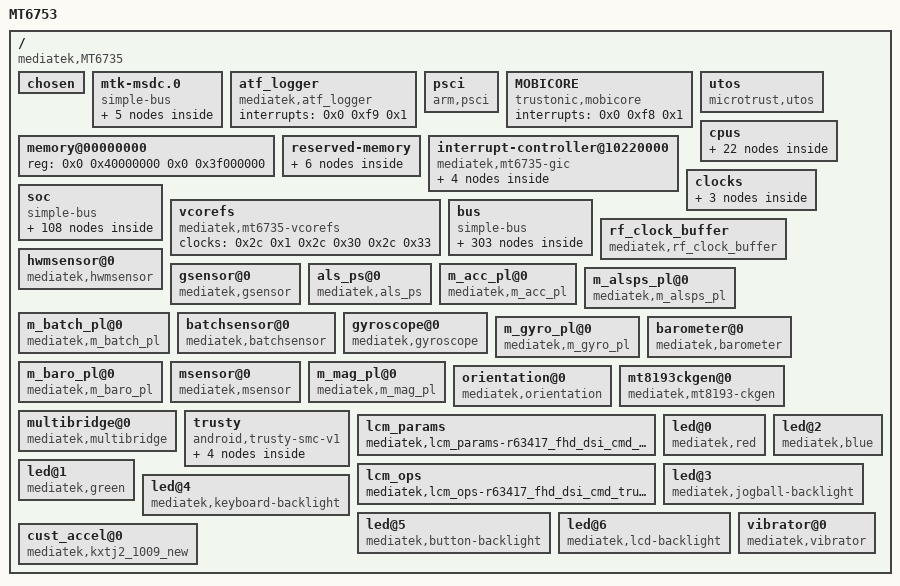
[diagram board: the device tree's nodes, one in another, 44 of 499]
/dts-v1/;

/ {
	model = "MT6753";
	compatible = "mediatek,MT6735";
	interrupt-parent = <0x1>;
	#address-cells = <0x2>;
	#size-cells = <0x2>;

	chosen {
		bootargs = "console=tty0 console=ttyMT0,921600n1 root=/dev/ram initrd=0x44000000,0x300000 loglevel=8 androidboot.hardware=mt6735";
	};

	mtk-msdc.0 {
		compatible = "simple-bus";
		#address-cells = <0x1>;
		#size-cells = <0x1>;
		ranges = <0x0 0x0 0x0 0xffffffff>;

		msdc0@11230000 {
			compatible = "mediatek,mt6753-mmc";
			reg = <0x11230000 0x10000 0x10000e84 0x2>;
			interrupts = <0x0 0x4f 0x8>;
			status = "okay";
			clk_src = [02];
			bus-width = <0x8>;
			max-frequency = <0xbebc200>;
			cap-mmc-highspeed;
			msdc-sys-suspend;
			mmc-ddr-1_8v;
			mmc-hs200-1_8v;
			mmc-hs400-1_8v;
			non-removable;
			pinctl = <0x2>;
			register_setting = <0x3>;
			host_function = [00];
			bootable;
		};

		msdc1@11240000 {
			compatible = "mediatek,mt6753-mmc";
			reg = <0x11240000 0x10000 0x10000e84 0x2>;
			interrupts = <0x0 0x50 0x8>;
			status = "okay";
			clk_src = [02];
			bus-width = <0x4>;
			max-frequency = <0xbebc200>;
			msdc-sys-suspend;
			sd_need_power;
			cap-sd-highspeed;
			sd-uhs-sdr12;
			sd-uhs-sdr25;
			sd-uhs-sdr50;
			sd-uhs-ddr50;
			pinctl = <0x4>;
			pinctl_sdr104 = <0x5>;
			pinctl_sdr50 = <0x6>;
			pinctl_ddr50 = <0x7>;
			register_setting = <0x8>;
			host_function = [01];
			cd_level = [00];
			cd-gpios = <0x9 0x4c 0x0>;
		};

		msdc2@11250000 {
			compatible = "mediatek,mt6735-mmc";
			reg = <0x11250000 0x10000 0x10000e84 0x2>;
			interrupts = <0x0 0x51 0x8>;
			status = "okay";
			clocks = <0xa 0x10>;
			clock-names = "MSDC2-CLOCK";
			clk_src = [02];
			bus-width = <0x4>;
			max-frequency = <0xbebc200>;
			cap-sd-highspeed;
			sd-uhs-sdr12;
			sd-uhs-sdr25;
			sd-uhs-sdr50;
			sd-uhs-sdr104;
			sd-uhs-ddr50;
			non-removable;
			host_function = [02];
		};

		msdc3@11260000 {
			compatible = "mediatek,mt6735-mmc";
			reg = <0x11260000 0x10000 0x10000e84 0x2>;
			interrupts = <0x0 0x52 0x8>;
			status = "disabled";
			clocks = <0xa 0x11>;
			clock-names = "MSDC3-CLOCK";
		};

		default {
			compatible = "mediatek, msdc1_ins-eint";
			interrupt-parent = <0xb>;
			interrupts = <0x4c 0x8>;
			debounce = <0x4c 0x3e8>;
			status = "okay";
		};
	};

	atf_logger {
		compatible = "mediatek,atf_logger";
		interrupts = <0x0 0xf9 0x1>;
	};

	psci {
		compatible = "arm,psci";
		method = "smc";
		cpu_suspend = <0x84000001>;
		cpu_off = <0x84000002>;
		cpu_on = <0x84000003>;
		affinity_info = <0x84000004>;
	};

	MOBICORE {
		compatible = "trustonic,mobicore";
		interrupts = <0x0 0xf8 0x1>;
	};

	utos {
		compatible = "microtrust,utos";
		interrupts = <0x0 0xf4 0x1 0x0 0xf5 0x1 0x0 0xf6 0x1 0x0 0xfa 0x1 0x0 0xfb 0x1 0x0 0xfc 0x1 0x0 0xfd 0x1 0x0 0xff 0x1>;
	};

	cpus {
		#address-cells = <0x1>;
		#size-cells = <0x0>;

		cpu@000 {
			device_type = "cpu";
			compatible = "arm,cortex-a53";
			reg = <0x0>;
			enable-method = "mt-boot";
			cpu-idle-states = <0xc 0xc 0xd 0xd>;
			cpu-release-addr = <0x0 0x40000200>;
			clock-frequency = "M|m";
			linux,phandle = <0xe>;
			phandle = <0xe>;
		};

		cpu@001 {
			device_type = "cpu";
			compatible = "arm,cortex-a53";
			reg = <0x1>;
			enable-method = "mt-boot";
			cpu-idle-states = <0xc 0xc 0xd 0xd>;
			cpu-release-addr = <0x0 0x40000200>;
			clock-frequency = "M|m";
			linux,phandle = <0xf>;
			phandle = <0xf>;
		};

		cpu@002 {
			device_type = "cpu";
			compatible = "arm,cortex-a53";
			reg = <0x2>;
			enable-method = "mt-boot";
			cpu-idle-states = <0xc 0xc 0xd 0xd>;
			cpu-release-addr = <0x0 0x40000200>;
			clock-frequency = "M|m";
			linux,phandle = <0x10>;
			phandle = <0x10>;
		};

		cpu@003 {
			device_type = "cpu";
			compatible = "arm,cortex-a53";
			reg = <0x3>;
			enable-method = "mt-boot";
			cpu-idle-states = <0xc 0xc 0xd 0xd>;
			cpu-release-addr = <0x0 0x40000200>;
			clock-frequency = "M|m";
			linux,phandle = <0x11>;
			phandle = <0x11>;
		};

		cpu@100 {
			device_type = "cpu";
			compatible = "arm,cortex-a53";
			reg = <0x100>;
			enable-method = "mt-boot";
			cpu-idle-states = <0xc 0xc 0xd 0xd>;
			cpu-release-addr = <0x0 0x40000200>;
			clock-frequency = "M|m";
			linux,phandle = <0x12>;
			phandle = <0x12>;
		};

		cpu@101 {
			device_type = "cpu";
			compatible = "arm,cortex-a53";
			reg = <0x101>;
			enable-method = "mt-boot";
			cpu-idle-states = <0xc 0xc 0xd 0xd>;
			cpu-release-addr = <0x0 0x40000200>;
			clock-frequency = "M|m";
			linux,phandle = <0x13>;
			phandle = <0x13>;
		};

		cpu@102 {
			device_type = "cpu";
			compatible = "arm,cortex-a53";
			reg = <0x102>;
			enable-method = "mt-boot";
			cpu-idle-states = <0xc 0xc 0xd 0xd>;
			cpu-release-addr = <0x0 0x40000200>;
			clock-frequency = "M|m";
			linux,phandle = <0x14>;
			phandle = <0x14>;
		};

		cpu@103 {
			device_type = "cpu";
			compatible = "arm,cortex-a53";
			reg = <0x103>;
			enable-method = "mt-boot";
			cpu-idle-states = <0xc 0xc 0xd 0xd>;
			cpu-release-addr = <0x0 0x40000200>;
			clock-frequency = "M|m";
			linux,phandle = <0x15>;
			phandle = <0x15>;
		};

		cpu-map {

			cluster0 {

				core0 {
					cpu = <0xe>;
				};

				core1 {
					cpu = <0xf>;
				};

				core2 {
					cpu = <0x10>;
				};

				core3 {
					cpu = <0x11>;
				};
			};

			cluster1 {

				core0 {
					cpu = <0x12>;
				};

				core1 {
					cpu = <0x13>;
				};

				core2 {
					cpu = <0x14>;
				};

				core3 {
					cpu = <0x15>;
				};
			};
		};

		idle-states {
			entry-method = "arm,psci";

			cpu-sleep-0-0 {
				compatible = "arm,idle-state";
				arm,psci-suspend-param = <0x10000>;
				entry-latency-us = <0x258>;
				exit-latency-us = <0x258>;
				min-residency-us = <0x4b0>;
				linux,phandle = <0xd>;
				phandle = <0xd>;
			};

			cluster-sleep-0 {
				compatible = "arm,idle-state";
				arm,psci-suspend-param = <0x1010000>;
				entry-latency-us = <0x320>;
				exit-latency-us = <0x3e8>;
				min-residency-us = <0x7d0>;
				linux,phandle = <0xc>;
				phandle = <0xc>;
			};
		};
	};

	memory@00000000 {
		device_type = "memory";
		reg = <0x0 0x40000000 0x0 0x3f000000>;
	};

	reserved-memory {
		#address-cells = <0x2>;
		#size-cells = <0x2>;
		ranges;

		atf-reserved-memory@43000000 {
			compatible = "mediatek,mt6735-atf-reserved-memory", "mediatek,mt6735m-atf-reserved-memory", "mediatek,mt6753-atf-reserved-memory";
			no-map;
			reg = <0x0 0x43000000 0x0 0x30000>;
		};

		reserve-memory-ccci_md1 {
			compatible = "mediatek,reserve-memory-ccci_md1";
			no-map;
			size = <0x0 0x3810000>;
			alignment = <0x0 0x2000000>;
			alloc-ranges = <0x0 0x40000000 0x0 0xc0000000>;
		};

		consys-reserve-memory {
			compatible = "mediatek,consys-reserve-memory";
			no-map;
			size = <0x0 0x100000>;
			alignment = <0x0 0x200000>;
		};

		ram_console-reserved-memory@43f00000 {
			compatible = "mediatek,ram_console";
			reg = <0x0 0x43f00000 0x0 0x10000>;
		};

		minirdump-reserved-memory@43ff0000 {
			compatible = "mediatek, minirdump";
			reg = <0x0 0x43ff0000 0x0 0x10000>;
		};

		pstore-reserved-memory@43f10000 {
			compatible = "mediatek,pstore";
			reg = <0x0 0x43f10000 0x0 0xe0000>;
		};
	};

	interrupt-controller@10220000 {
		compatible = "mediatek,mt6735-gic";
		#interrupt-cells = <0x3>;
		#address-cells = <0x0>;
		interrupt-controller;
		reg = <0x0 0x10221000 0x0 0x1000 0x0 0x10222000 0x0 0x1000 0x0 0x10200620 0x0 0x1000>;
		mediatek,wdt_irq = <0xa0>;
		linux,phandle = <0x1>;
		phandle = <0x1>;

		gic-cpuif@0 {
			compatible = "arm,gic-cpuif";
			cpuif-id = <0x0>;
			cpu = <0xe>;
		};

		gic-cpuif@1 {
			compatible = "arm,gic-cpuif";
			cpuif-id = <0x1>;
			cpu = <0xf>;
		};

		gic-cpuif@2 {
			compatible = "arm,gic-cpuif";
			cpuif-id = <0x2>;
			cpu = <0x10>;
		};

		gic-cpuif@3 {
			compatible = "arm,gic-cpuif";
			cpuif-id = <0x3>;
			cpu = <0x11>;
		};
	};

	clocks {

		clk_null {
			compatible = "fixed-clock";
			#clock-cells = <0x0>;
			clock-frequency = <0x0>;
		};

		clk26m {
			compatible = "fixed-clock";
			#clock-cells = <0x0>;
			clock-frequency = <0x18cba80>;
		};

		clk32k {
			compatible = "fixed-clock";
			#clock-cells = <0x0>;
			clock-frequency = <0x7d00>;
		};
	};

	soc {
		compatible = "simple-bus";
		#address-cells = <0x1>;
		#size-cells = <0x1>;
		ranges;

		chipid@08000000 {
			compatible = "mediatek,chipid";
			reg = <0x8000000 0x4 0x8000004 0x4 0x8000008 0x4 0x800000c 0x4>;
		};

		topckgen@0x10210000 {
			compatible = "mediatek,mt6735-topckgen";
			reg = <0x10210000 0x1000>;
			#clock-cells = <0x1>;
			linux,phandle = <0x2c>;
			phandle = <0x2c>;
		};

		infrasys@0x10000000 {
			compatible = "mediatek,mt6735-infrasys";
			reg = <0x10000000 0x1000>;
			#clock-cells = <0x1>;
			linux,phandle = <0x16>;
			phandle = <0x16>;
		};

		perisys@0x10002000 {
			compatible = "mediatek,mt6735-perisys";
			reg = <0x10002000 0x1000>;
			#clock-cells = <0x1>;
			linux,phandle = <0xa>;
			phandle = <0xa>;
		};

		gpio {
			compatible = "mediatek,gpio_usage_mapping";
			GPIO_SIM1_HOT_PLUG = <0x8>;
			GPIO_SIM2_SCLK = <0xa0>;
			GPIO_SIM2_SRST = <0xa1>;
			GPIO_SIM2_SIO = <0xa2>;
			GPIO_SIM1_SCLK = <0xa3>;
			GPIO_SIM1_SRST = <0xa4>;
			GPIO_SIM1_SIO = <0xa5>;
		};

		gpio@10211000 {
			compatible = "mediatek,gpio";
			reg = <0x10211000 0x1000>;
		};

		dramc_nao@1020e000 {
			compatible = "mediatek,mt6735-dramc_nao";
			reg = <0x1020e000 0x1000>;
		};

		ddrphy@10213000 {
			compatible = "mediatek,mt6735-ddrphy";
			reg = <0x10213000 0x1000>;
		};

		dramc@10214000 {
			compatible = "mediatek,mt6735-dramc";
			reg = <0x10214000 0x1000>;
			clocks = <0x16 0x2>;
			clock-names = "infra-cqdma";
		};

		cpuxgpt@10200000 {
			compatible = "mediatek,mt6735-cpuxgpt";
			reg = <0x10200000 0x1000>;
			interrupts = <0x0 0x40 0x4 0x0 0x41 0x4 0x0 0x42 0x4 0x0 0x43 0x4 0x0 0x44 0x4 0x0 0x45 0x4 0x0 0x46 0x4 0x0 0x47 0x4>;
		};

		apxgpt@10004000 {
			compatible = "mediatek,mt6735-apxgpt";
			reg = <0x10004000 0x1000>;
			interrupts = <0x0 0x98 0x8>;
			clock-frequency = <0xc65d40>;
		};

		pmu {
			compatible = "arm,armv8-pmuv3";
			interrupts = <0x0 0x8 0x8 0x0 0x9 0x8 0x0 0xa 0x8 0x0 0xb 0x8 0x0 0xc 0x8 0x0 0xd 0x8 0x0 0xe 0x8 0x0 0xf 0x8>;
			interrupt-affinity = <0xe 0xf 0x10 0x11 0x12 0x13 0x14 0x15>;
		};

		timer {
			compatible = "arm,armv8-timer";
			interrupts = <0x1 0xd 0x8 0x1 0xe 0x8 0x1 0xb 0x8 0x1 0xa 0x8>;
			clock-frequency = <0xc65d40>;
		};

		mt_pmic_regulator {
			compatible = "mediatek,mt_pmic";

			buck_regulators {
				compatible = "mediatek,mt_pmic_buck_regulators";

				buck_vpa {
					regulator-name = "vpa";
					regulator-min-microvolt = <0x7a120>;
					regulator-max-microvolt = <0x37b1d0>;
					regulator-ramp-delay = <0xc350>;
					regulator-enable-ramp-delay = <0xb4>;
				};

				buck_vproc {
					regulator-name = "vproc";
					regulator-min-microvolt = <0x927c0>;
					regulator-max-microvolt = <0x154456>;
					regulator-ramp-delay = <0x186a>;
					regulator-enable-ramp-delay = <0xb4>;
					regulator-always-on;
					regulator-boot-on;
				};

				buck_vcore1 {
					regulator-name = "vcore1";
					regulator-min-microvolt = <0x927c0>;
					regulator-max-microvolt = <0x154456>;
					regulator-ramp-delay = <0x186a>;
					regulator-enable-ramp-delay = <0xb4>;
					regulator-always-on;
					regulator-boot-on;
				};

				buck_vsys22 {
					regulator-name = "vsys22";
					regulator-min-microvolt = <0x124f80>;
					regulator-max-microvolt = <0x1e6c16>;
					regulator-ramp-delay = <0x186a>;
					regulator-enable-ramp-delay = <0xb4>;
					regulator-always-on;
					regulator-boot-on;
				};

				buck_vlte {
					regulator-name = "vlte";
					regulator-min-microvolt = <0x927c0>;
					regulator-max-microvolt = <0x154456>;
					regulator-ramp-delay = <0x186a>;
					regulator-enable-ramp-delay = <0xb4>;
					regulator-always-on;
					regulator-boot-on;
				};
			};

			ldo_regulators {
				compatible = "mediatek,mt_pmic_ldo_regulators";

				ldo_vaux18 {
					regulator-name = "vaux18";
					regulator-min-microvolt = <0x1b7740>;
					regulator-max-microvolt = <0x1b7740>;
					regulator-enable-ramp-delay = <0x108>;
					regulator-boot-on;
					linux,phandle = <0x17>;
					phandle = <0x17>;
				};

				ldo_vtcxo_0 {
					regulator-name = "vtcxo_0";
					regulator-min-microvolt = <0x2ab980>;
					regulator-max-microvolt = <0x2ab980>;
					regulator-enable-ramp-delay = <0x6e>;
					regulator-boot-on;
					linux,phandle = <0x18>;
					phandle = <0x18>;
				};

				ldo_vtcxo_1 {
					regulator-name = "vtcxo_1";
					regulator-min-microvolt = <0x2ab980>;
					regulator-max-microvolt = <0x2ab980>;
					regulator-enable-ramp-delay = <0x6e>;
					linux,phandle = <0x19>;
					phandle = <0x19>;
				};

				ldo_vaud28 {
					regulator-name = "vaud28";
					regulator-min-microvolt = <0x2ab980>;
					regulator-max-microvolt = <0x2ab980>;
					regulator-enable-ramp-delay = <0x108>;
					regulator-boot-on;
					linux,phandle = <0x1a>;
					phandle = <0x1a>;
				};

				ldo_vcn28 {
					regulator-name = "vcn28";
					regulator-min-microvolt = <0x2ab980>;
					regulator-max-microvolt = <0x2ab980>;
					regulator-enable-ramp-delay = <0x108>;
				};

				ldo_vcama {
					regulator-name = "vcama";
					regulator-min-microvolt = <0x16e360>;
					regulator-max-microvolt = <0x2ab980>;
					regulator-enable-ramp-delay = <0x108>;
					regulator-default-on = <0x0>;
					status = "okay";
					linux,phandle = <0x38>;
					phandle = <0x38>;
				};

				ldo_vcn33_bt {
					regulator-name = "vcn33_bt";
					regulator-min-microvolt = <0x325aa0>;
					regulator-max-microvolt = <0x36ee80>;
					regulator-enable-ramp-delay = <0x108>;
				};

				ldo_vcn33_wifi {
					regulator-name = "vcn33_wifi";
					regulator-min-microvolt = <0x325aa0>;
					regulator-max-microvolt = <0x36ee80>;
					regulator-enable-ramp-delay = <0x108>;
				};

				ldo_vusb33 {
					regulator-name = "vusb33";
					regulator-min-microvolt = <0x325aa0>;
					regulator-max-microvolt = <0x325aa0>;
					regulator-enable-ramp-delay = <0x108>;
					regulator-boot-on;
					linux,phandle = <0x62>;
					phandle = <0x62>;
				};

				ldo_vefuse {
					regulator-name = "vefuse";
					regulator-min-microvolt = <0x1b7740>;
					regulator-max-microvolt = <0x2191c0>;
					regulator-enable-ramp-delay = <0x108>;
					linux,phandle = <0x1b>;
					phandle = <0x1b>;
				};

				ldo_vsim1 {
					regulator-name = "vsim1";
					regulator-min-microvolt = <0x19f0a0>;
					regulator-max-microvolt = <0x200b20>;
					regulator-enable-ramp-delay = <0x108>;
					regulator-default-on = <0x0>;
					status = "okay";
					linux,phandle = <0x1c>;
					phandle = <0x1c>;
				};

				ldo_vsim2 {
					regulator-name = "vsim2";
					regulator-min-microvolt = <0x19f0a0>;
					regulator-max-microvolt = <0x200b20>;
					regulator-enable-ramp-delay = <0x108>;
					regulator-default-on = <0x0>;
					status = "okay";
					linux,phandle = <0x1d>;
					phandle = <0x1d>;
				};

				ldo_vemc_3v3 {
					regulator-name = "vemc_3v3";
					regulator-min-microvolt = <0x1b7740>;
					regulator-max-microvolt = <0x325aa0>;
					regulator-enable-ramp-delay = <0x108>;
					regulator-boot-on;
					linux,phandle = <0x1e>;
					phandle = <0x1e>;
				};

				ldo_vmch {
					regulator-name = "vmch";
					regulator-min-microvolt = <0x2c4020>;
					regulator-max-microvolt = <0x325aa0>;
					regulator-enable-ramp-delay = <0x2c>;
					linux,phandle = <0x1f>;
					phandle = <0x1f>;
				};

				ldo_vtref {
					regulator-name = "vtref";
					regulator-min-microvolt = <0x1b7740>;
					regulator-max-microvolt = <0x1b7740>;
					regulator-enable-ramp-delay = <0xf0>;
					linux,phandle = <0x20>;
					phandle = <0x20>;
				};

				ldo_vmc {
					regulator-name = "vmc";
					regulator-min-microvolt = <0x1b7740>;
					regulator-max-microvolt = <0x325aa0>;
					regulator-enable-ramp-delay = <0x2c>;
					linux,phandle = <0x21>;
					phandle = <0x21>;
				};

				ldo_vcamaf {
					regulator-name = "vcamaf";
					regulator-min-microvolt = <0x124f80>;
					regulator-max-microvolt = <0x325aa0>;
					regulator-enable-ramp-delay = <0x108>;
					regulator-default-on = <0x0>;
					status = "okay";
					linux,phandle = <0x3a>;
					phandle = <0x3a>;
				};

				ldo_vio28 {
					regulator-name = "vio28";
					regulator-min-microvolt = <0x2ab980>;
					regulator-max-microvolt = <0x2ab980>;
					regulator-enable-ramp-delay = <0x108>;
					regulator-boot-on;
					linux,phandle = <0x22>;
					phandle = <0x22>;
				};

				ldo_vgp1 {
					regulator-name = "vgp1";
					regulator-min-microvolt = <0x124f80>;
					regulator-max-microvolt = <0x325aa0>;
					regulator-enable-ramp-delay = <0x108>;
					regulator-default-on = <0x0>;
					status = "okay";
					linux,phandle = <0x71>;
					phandle = <0x71>;
				};

				ldo_vibr {
					regulator-name = "vibr";
					regulator-min-microvolt = <0x124f80>;
					regulator-max-microvolt = <0x325aa0>;
					regulator-enable-ramp-delay = <0x2c>;
					regulator-default-on = <0x0>;
					status = "okay";
					linux,phandle = <0x23>;
					phandle = <0x23>;
				};

				ldo_vcamd {
					regulator-name = "vcamd";
					regulator-min-microvolt = <0xdbba0>;
					regulator-max-microvolt = <0x16e360>;
					regulator-enable-ramp-delay = <0x108>;
					regulator-default-on = <0x0>;
					status = "okay";
					linux,phandle = <0x39>;
					phandle = <0x39>;
				};

				ldo_vrf18_0 {
					regulator-name = "vrf18_0";
					regulator-min-microvolt = <0x1bd8e8>;
					regulator-max-microvolt = <0x1bd8e8>;
					regulator-enable-ramp-delay = <0xdc>;
					linux,phandle = <0x24>;
					phandle = <0x24>;
				};

				ldo_vrf18_1 {
					regulator-name = "vrf18_1";
					regulator-min-microvolt = <0x124f80>;
					regulator-max-microvolt = <0x1bd8e8>;
					regulator-enable-ramp-delay = <0xdc>;
					linux,phandle = <0x25>;
					phandle = <0x25>;
				};

				ldo_vio18 {
					regulator-name = "vio18";
					regulator-min-microvolt = <0x1b7740>;
					regulator-max-microvolt = <0x1b7740>;
					regulator-enable-ramp-delay = <0x108>;
					regulator-boot-on;
					linux,phandle = <0x26>;
					phandle = <0x26>;
				};

				ldo_vcn18 {
					regulator-name = "vcn18";
					regulator-min-microvolt = <0x1b7740>;
					regulator-max-microvolt = <0x1b7740>;
					regulator-enable-ramp-delay = <0x2c>;
				};

				ldo_vcamio {
					regulator-name = "vcamio";
					regulator-min-microvolt = <0x124f80>;
					regulator-max-microvolt = <0x1b7740>;
					regulator-enable-ramp-delay = <0xdc>;
					regulator-default-on = <0x0>;
					status = "okay";
					linux,phandle = <0x3b>;
					phandle = <0x3b>;
				};

				ldo_vsram {
					regulator-name = "vsram";
					regulator-min-microvolt = <0xaae60>;
					regulator-max-microvolt = <0x16caf6>;
					regulator-enable-ramp-delay = <0xdc>;
					regulator-ramp-delay = <0x186a>;
					regulator-boot-on;
					linux,phandle = <0x27>;
					phandle = <0x27>;
				};

				ldo_vm {
					regulator-name = "vm";
					regulator-min-microvolt = <0x12ebc0>;
					regulator-max-microvolt = <0x177fa0>;
					regulator-enable-ramp-delay = <0x108>;
					regulator-boot-on;
					linux,phandle = <0x28>;
					phandle = <0x28>;
				};
			};

			regulators_supply {
				compatible = "mediatek,mt_pmic_regulator_supply";
				vaux18-supply = <0x17>;
				vtcxo_0-supply = <0x18>;
				vtcxo_1-supply = <0x19>;
				vaud28-supply = <0x1a>;
				vefuse-supply = <0x1b>;
				vsim1-supply = <0x1c>;
				vsim2-supply = <0x1d>;
				vemc_3v3-supply = <0x1e>;
				vmch-supply = <0x1f>;
				vtref-supply = <0x20>;
				vmc-supply = <0x21>;
				vio28-supply = <0x22>;
				vibr-supply = <0x23>;
				vrf18_0-supply = <0x24>;
				vrf18_1-supply = <0x25>;
				vio18-supply = <0x26>;
				vsram-supply = <0x27>;
				vm-supply = <0x28>;
			};
		};

		sys_cirq@10204000 {
			compatible = "mediatek,mt6735-sys_cirq";
			reg = <0x10204000 0x1000>;
			interrupts = <0x0 0xe7 0x8>;
			mediatek,cirq_num = <0x9f>;
			mediatek,spi_start_offset = <0x48>;
		};

		apmixedsys@0x10209000 {
			compatible = "mediatek,mt6735-apmixedsys";
			reg = <0x10209000 0x1000>;
			#clock-cells = <0x1>;
		};

		toprgu@10212000 {
			compatible = "mediatek,mt6735-rgu";
			reg = <0x10212000 0x1000>;
			interrupts = <0x0 0x80 0x2>;
		};

		adc_hw@11001000 {
			compatible = "mediatek,mt6735-auxadc";
			reg = <0x11001000 0x1000>;
			interrupts = <0x0 0x4c 0x2>;
			clocks = <0xa 0x1c>;
			clock-names = "auxadc-main";

			adc_channel@ {
				compatible = "mediatek,adc_channel";
				mediatek,temperature0 = <0x0>;
				mediatek,temperature1 = <0x1>;
				mediatek,adc_fdd_rf_params_dynamic_custom_ch = <0xc>;
				status = "okay";
			};
		};

		audiosys@11220000 {
			compatible = "mediatek,mt6735-audiosys";
			reg = <0x11220000 0x10000>;
			#clock-cells = <0x1>;
		};

		mfgsys@0x13000000 {
			compatible = "mediatek,mt6735-mfgsys";
			reg = <0x13000000 0x1000>;
			#clock-cells = <0x1>;
			linux,phandle = <0x7a>;
			phandle = <0x7a>;
		};

		mmsys@0x14000000 {
			compatible = "mediatek,mt6735-mmsys";
			reg = <0x14000000 0x1000>;
			#clock-cells = <0x1>;
			linux,phandle = <0x29>;
			phandle = <0x29>;
		};

		imgsys@0x15000000 {
			compatible = "mediatek,mt6735-imgsys";
			reg = <0x15000000 0x1000>;
			#clock-cells = <0x1>;
			linux,phandle = <0x37>;
			phandle = <0x37>;
		};

		vdecsys@0x16000000 {
			compatible = "mediatek,mt6735-vdecsys";
			reg = <0x16000000 0x1000>;
			interrupts = <0x0 0xb3 0x8>;
			#clock-cells = <0x1>;
			linux,phandle = <0x2a>;
			phandle = <0x2a>;
		};

		vencsys@0x17000000 {
			compatible = "mediatek,mt6735-vencsys";
			reg = <0x17000000 0x1000>;
			interrupts = <0x0 0xb4 0x8>;
			#clock-cells = <0x1>;
			linux,phandle = <0x2b>;
			phandle = <0x2b>;
		};

		scpsys@0x10000000 {
			compatible = "mediatek,mt6735-scpsys";
			reg = <0x10000000 0x1000 0x10006000 0x1000>;
			#clock-cells = <0x1>;
			linux,phandle = <0x2d>;
			phandle = <0x2d>;
		};

		vdec_gcon@16000000 {
			compatible = "mediatek,mt6735-vdec_gcon";
			reg = <0x16000000 0x1000>;
			interrupts = <0x0 0xb3 0x8>;
			clocks = <0x29 0x1 0x2a 0x1 0x2a 0x2 0x2b 0x2 0x2b 0x1 0x2c 0x6 0x2c 0x32 0x2c 0x33 0x2d 0x7 0x2d 0x8 0x2d 0x4>;
			clock-names = "MT_CG_DISP0_SMI_COMMON", "MT_CG_VDEC0_VDEC", "MT_CG_VDEC1_LARB", "MT_CG_VENC_VENC", "MT_CG_VENC_LARB", "MT_CG_TOP_MUX_VDEC", "MT_CG_TOP_SYSPLL1_D2", "MT_CG_TOP_SYSPLL1_D4", "MT_SCP_SYS_VDE", "MT_SCP_SYS_VEN", "MT_SCP_SYS_DIS";
		};

		vdec@16020000 {
			compatible = "mediatek,mt6735-vdec";
			reg = <0x16020000 0x10000>;
			interrupts = <0x0 0xb3 0x8>;
		};

		venc_gcon@17000000 {
			compatible = "mediatek,mt6735-venc_gcon";
			reg = <0x17000000 0x1000>;
			interrupts = <0x0 0xb4 0x8>;
		};

		venc@17002000 {
			compatible = "mediatek,mt6735-venc";
			reg = <0x17002000 0x1000>;
			interrupts = <0x0 0xb4 0x8>;
		};

		jpgenc@17003000 {
			compatible = "mediatek,jpgenc";
			reg = <0x17003000 0x1000>;
			interrupts = <0x0 0xb5 0x8>;
			clocks = <0x2d 0x4 0x29 0x1 0x2d 0x8 0x2b 0x1 0x2b 0x3>;
			clock-names = "disp-mtcmos", "disp-smi", "venc-mtcmos", "venc-larb", "venc-jpgenc";
		};

		jpgdec@17004000 {
			compatible = "mediatek,jpgdec";
			reg = <0x17004000 0x1000>;
			interrupts = <0x0 0xd1 0x8>;
			clocks = <0x2d 0x4 0x29 0x1 0x2d 0x8 0x2b 0x1 0x2b 0x4>;
			clock-names = "disp-mtcmos", "disp-smi", "venc-mtcmos", "venc-larb", "venc-jpgdec";
		};

		keypad@10003000 {
			compatible = "mediatek,mt6735-keypad";
			reg = <0x10003000 0x1000>;
			interrupts = <0x0 0xa4 0x2>;
			mediatek,kpd-key-debounce = <0x400>;
			mediatek,kpd-sw-pwrkey = <0x74>;
			mediatek,kpd-hw-pwrkey = <0x8>;
			mediatek,kpd-use-extend-type = <0x0>;
			mediatek,kpd-hw-map-num = <0x48>;
			mediatek,kpd-hw-init-map = <0x72 0x73 0x0 0x0 0x0 0x0 0x0 0x0 0x0 0x0 0x0 0x0 0x0 0x0 0x0 0x0 0x0 0x0 0x0 0x0 0x0 0x0 0x0 0x0 0x0 0x0 0x0 0x0 0x0 0x0 0x0 0x0 0x0 0x0 0x0 0x0 0x0 0x0 0x0 0x0 0x0 0x0 0x0 0x0 0x0 0x0 0x0 0x0 0x0 0x0 0x0 0x0 0x0 0x0 0x0 0x0 0x0 0x0 0x0 0x0 0x0 0x0 0x0 0x0 0x0 0x0 0x0 0x0 0x0 0x0 0x0 0x0>;
			mediatek,kpd-pwrkey-eint-gpio = <0x0>;
			mediatek,kpd-pwkey-gpio-din = <0x0>;
			mediatek,kpd-hw-dl-key0 = <0x1>;
			mediatek,kpd-hw-dl-key1 = <0x0>;
			mediatek,kpd-hw-dl-key2 = <0x8>;
			mediatek,kpd-hw-recovery-key = <0x1>;
			mediatek,kpd-hw-factory-key = <0x0>;
			status = "okay";
		};

		irtx@11011000 {
			compatible = "mediatek,irtx";
			reg = <0x11011000 0x1000>;
			interrupts = <0x0 0x7c 0x4>;
			pwm_ch = <0x0>;
			clock-frequency = <0x18cba80>;
			clock-div = <0x1>;
			clocks = <0xa 0x1e>;
			clock-names = "clk-irtx-main";
		};

		apuart0@11002000 {
			cell-index = <0x0>;
			compatible = "mediatek,mt6735-uart";
			reg = <0x11002000 0x1000 0x11000400 0x1000 0x11000480 0x80>;
			interrupts = <0x0 0x5b 0x8 0x0 0x67 0x8 0x0 0x68 0x8>;
			clock-frequency = <0x18cba80>;
			clock-div = <0x1>;
			clocks = <0xa 0x12 0xa 0xd>;
			clock-names = "uart0-main", "uart-apdma";
			pinctrl-names = "default", "uart0_rx_set", "uart0_rx_clear", "uart0_tx_set", "uart0_tx_clear";
			pinctrl-0 = <0x2e>;
			pinctrl-1 = <0x2f>;
			pinctrl-2 = <0x30>;
			pinctrl-3 = <0x31>;
			pinctrl-4 = <0x32>;
		};

		apuart1@11003000 {
			cell-index = <0x1>;
			compatible = "mediatek,mt6735-uart";
			reg = <0x11003000 0x1000 0x11000500 0x80 0x11000580 0x80>;
			interrupts = <0x0 0x5c 0x8 0x0 0x69 0x8 0x0 0x6a 0x8>;
			clock-frequency = <0x18cba80>;
			clock-div = <0x1>;
			clocks = <0xa 0x13>;
			clock-names = "uart1-main";
		};

		apuart2@11004000 {
			cell-index = <0x2>;
			compatible = "mediatek,mt6735-uart";
			reg = <0x11004000 0x1000 0x11000600 0x80 0x11000680 0x80>;
			interrupts = <0x0 0x5d 0x8 0x0 0x6b 0x8 0x0 0x6c 0x8>;
			clock-frequency = <0x18cba80>;
			clock-div = <0x1>;
			clocks = <0xa 0x14>;
			clock-names = "uart2-main";
		};

		apuart3@11005000 {
			cell-index = <0x3>;
			compatible = "mediatek,mt6735-uart";
			reg = <0x11005000 0x1000 0x11000700 0x80 0x11000780 0x80>;
			interrupts = <0x0 0x5e 0x8 0x0 0x6d 0x8 0x0 0x6e 0x8>;
			clock-frequency = <0x18cba80>;
			clock-div = <0x1>;
			clocks = <0xa 0x15>;
			clock-names = "uart3-main";
		};

		THERM_CTRL@0x1100B000 {
			compatible = "mediatek,THERM_CTRL";
			reg = <0x1100b000 0x1000>;
			interrupts = <0x0 0x4e 0x8>;
		};

		ptp_fsm@1100b000 {
			compatible = "mediatek,ptp_fsm_v1";
			reg = <0x1100b000 0x1000>;
			interrupts = <0x0 0x7d 0x8>;
		};

		apuart4@1100d000 {
			cell-index = <0x4>;
			compatible = "mediatek,mt6735-uart";
			reg = <0x1100d000 0x1000 0x11000800 0x80 0x11000880 0x80>;
			interrupts = <0x0 0x5f 0x8 0x0 0x6f 0x8 0x0 0x70 0x8>;
			clock-frequency = <0x18cba80>;
			clock-div = <0x1>;
			clocks = <0xa 0x16>;
			clock-names = "uart4-main";
		};

		spi@1100a000 {
			compatible = "mediatek,mt6753-spi";
			cell-index = <0x0>;
			spi-padmacro = <0x0>;
			reg = <0x1100a000 0x1000>;
			interrupts = <0x0 0x76 0x8>;
		};

		btif_tx@11000900 {
			compatible = "mediatek,btif_tx";
			reg = <0x11000900 0x80>;
			interrupts = <0x0 0x71 0x8>;
		};

		btif_rx@11000980 {
			compatible = "mediatek,btif_rx";
			reg = <0x11000980 0x80>;
			interrupts = <0x0 0x72 0x8>;
		};

		btif@1100c000 {
			compatible = "mediatek,btif";
			reg = <0x1100c000 0x1000>;
			interrupts = <0x0 0x5a 0x8>;
		};

		consys@18070000 {
			compatible = "mediatek,mt6753-consys", "mediatek,mt6735-consys";
			reg = <0x18070000 0x200 0x10212000 0x100 0x10000000 0x2000 0x10006000 0x1000>;
			interrupts = <0x0 0xe5 0x8 0x0 0xe3 0x8>;
			pinctrl-names = "default", "gps_lna_state_init", "gps_lna_state_oh", "gps_lna_state_ol";
			pinctrl-0 = <0x33>;
			pinctrl-1 = <0x34>;
			pinctrl-2 = <0x35>;
			pinctrl-3 = <0x36>;
			status = "okay";
		};

		met_smi@14017000 {
			compatible = "mediatek,met_smi";
			reg = <0x14017000 0x1000 0x14016000 0x1000 0x16010000 0x1000 0x15001000 0x1000 0x17001000 0x1000>;
		};

		gce@10217000 {
			compatible = "mediatek,gce";
			reg = <0x10217000 0x1000>;
			interrupts = <0x0 0x97 0x8 0x0 0x94 0x8>;
			disp_mutex_reg = <0x14015000 0x1000>;
			g3d_config_base = <0x13000000 0x0 0xffff0000>;
			mmsys_config_base = <0x14000000 0x1 0xffff0000>;
			disp_dither_base = <0x14010000 0x2 0xffff0000>;
			mm_na_base = <0x14020000 0x3 0xffff0000>;
			imgsys_base = <0x15000000 0x4 0xffff0000>;
			vdec_gcon_base = <0x16000000 0x5 0xffff0000>;
			venc_gcon_base = <0x17000000 0x6 0xffff0000>;
			conn_peri_base = <0x18000000 0x7 0xffff0000>;
			topckgen_base = <0x10000000 0x8 0xffff0000>;
			kp_base = <0x10010000 0x9 0xffff0000>;
			scp_sram_base = <0x10020000 0xa 0xffff0000>;
			infra_na3_base = <0x10030000 0xb 0xffff0000>;
			infra_na4_base = <0x10040000 0xc 0xffff0000>;
			scp_base = <0x10050000 0xd 0xffff0000>;
			mcucfg_base = <0x10200000 0xe 0xffff0000>;
			gcpu_base = <0x10210000 0xf 0xffff0000>;
			usb0_base = <0x11200000 0x10 0xffff0000>;
			usb_sif_base = <0x11210000 0x11 0xffff0000>;
			audio_base = <0x11220000 0x12 0xffff0000>;
			msdc0_base = <0x11230000 0x13 0xffff0000>;
			msdc1_base = <0x11240000 0x14 0xffff0000>;
			msdc2_base = <0x11250000 0x15 0xffff0000>;
			msdc3_base = <0x11260000 0x16 0xffff0000>;
			pwm_sw_base = <0x1100e000 0x63 0xfffff000>;
			mdp_rdma0_sof = <0x0>;
			mdp_rsz0_sof = <0x1>;
			mdp_rsz1_sof = <0x2>;
			mdp_tdshp_sof = <0x3>;
			mdp_wdma_sof = <0x4>;
			mdp_wrot_sof = <0x5>;
			disp_ovl0_sof = <0x6>;
			disp_ovl1_sof = <0x7>;
			disp_rdma0_sof = <0x8>;
			disp_rdma1_sof = <0x9>;
			disp_wdma0_sof = <0xa>;
			disp_ccorr_sof = <0xb>;
			disp_color_sof = <0xc>;
			disp_aal_sof = <0xd>;
			disp_gamma_sof = <0xe>;
			disp_dither_sof = <0xf>;
			disp_pwm0_sof = <0x11>;
			disp_od_sof = <0x12>;
			mdp_rdma0_frame_done = <0x13>;
			mdp_rsz0_frame_done = <0x14>;
			mdp_rsz1_frame_done = <0x15>;
			mdp_tdshp_frame_done = <0x16>;
			mdp_wdma_frame_done = <0x17>;
			mdp_wrot_write_frame_done = <0x18>;
			mdp_wrot_read_frame_done = <0x19>;
			disp_ovl0_frame_done = <0x1a>;
			disp_ovl1_frame_done = <0x1b>;
			disp_rdma0_frame_done = <0x1c>;
			disp_rdma1_frame_done = <0x1d>;
			disp_wdma0_frame_done = <0x1e>;
			disp_ccorr_frame_done = <0x1f>;
			disp_color_frame_done = <0x20>;
			disp_aal_frame_done = <0x21>;
			disp_gamma_frame_done = <0x22>;
			disp_dither_frame_done = <0x23>;
			disp_od_frame_done = <0x25>;
			disp_dpi0_frame_done = <0x26>;
			disp_dsi0_frame_done = <0x27>;
			stream_done_0 = <0x28>;
			stream_done_1 = <0x29>;
			stream_done_2 = <0x2a>;
			stream_done_3 = <0x2b>;
			stream_done_4 = <0x2c>;
			stream_done_5 = <0x2d>;
			stream_done_6 = <0x2e>;
			stream_done_7 = <0x2f>;
			stream_done_8 = <0x30>;
			stream_done_9 = <0x31>;
			buf_underrun_event_0 = <0x32>;
			buf_underrun_event_1 = <0x33>;
			dsi0_te_event = <0x34>;
			isp_frame_done_p2_2 = <0x41>;
			isp_frame_done_p2_1 = <0x42>;
			isp_frame_done_p2_0 = <0x43>;
			isp_frame_done_p1_1 = <0x44>;
			isp_frame_done_p1_0 = <0x45>;
			camsv_2_pass1_done = <0x46>;
			camsv_1_pass1_done = <0x47>;
			seninf_cam1_2_3_fifo_full = <0x48>;
			seninf_cam0_fifo_full = <0x49>;
			venc_done = <0x81>;
			jpgenc_done = <0x82>;
			jpgdec_done = <0x83>;
			venc_mb_done = <0x84>;
			venc_128byte_cnt_done = <0x85>;
			apxgpt2_count = <0x10004028>;
		};

		smi_larb0@14016000 {
			compatible = "mediatek,smi_larb0";
			reg = <0x14016000 0x1000>;
		};

		smi_larb1@16010000 {
			compatible = "mediatek,smi_larb1";
			reg = <0x16010000 0x1000>;
			interrupts = <0x0 0xb1 0x8>;
		};

		smi_larb2@15001000 {
			compatible = "mediatek,smi_larb2";
			reg = <0x15001000 0x1000>;
			interrupts = <0x0 0xb2 0x8>;
		};

		smi_larb3@17001000 {
			compatible = "mediatek,smi_larb3";
			reg = <0x17001000 0x1000>;
			interrupts = <0x0 0xca 0x8>;
		};

		smi_common@14017000 {
			compatible = "mediatek,smi_common";
			reg = <0x14017000 0x1000 0x14016000 0x1000 0x16010000 0x1000 0x15001000 0x1000 0x17001000 0x1000>;
			clocks = <0x29 0x1 0x29 0x2 0x37 0x1 0x2a 0x1 0x2a 0x2 0x2b 0x1 0x2b 0x2 0x2d 0x8 0x2d 0x7 0x2d 0x6 0x2d 0x4>;
			clock-names = "smi-common", "smi-larb0", "img-larb2", "vdec0-vdec", "vdec1-larb", "venc-larb", "venc-venc", "mtcmos-ven", "mtcmos-vde", "mtcmos-isp", "mtcmos-dis";
		};

		ispsys@15000000 {
			compatible = "mediatek,mt6735-ispsys";
			reg = <0x15004000 0x9000 0x1500d000 0x1000 0x15000000 0x10000 0x10215000 0x3000 0x10211000 0x1000>;
			interrupts = <0x0 0xb7 0x8 0x0 0xb8 0x8 0x0 0xb9 0x8 0x0 0xce 0x8 0x0 0xcf 0x8>;
		};

		kd_camera_hw1@15008000 {
			compatible = "mediatek,camera_hw";
			reg = <0x15008000 0x1000>;
			vcama-supply = <0x38>;
			vcamd-supply = <0x39>;
			vcamaf-supply = <0x3a>;
			vcamio-supply = <0x3b>;
			vcama_main2-supply = <0x38>;
			vcama_sub-supply = <0x38>;
			vcamaf_main2-supply = <0x3a>;
			vcamaf_sub-supply = <0x3a>;
			vcamd_main2-supply = <0x39>;
			vcamd_sub-supply = <0x39>;
			vcamio_main2-supply = <0x3b>;
			vcamio_sub-supply = <0x3b>;
			status = "okay";
			pinctrl-names = "default", "cam0_rst0", "cam0_rst1", "cam0_pnd0", "cam0_pnd1", "cam1_rst0", "cam1_rst1", "cam1_pnd0", "cam1_pnd1", "cam_ldo0_0", "cam_ldo0_1";
			pinctrl-0 = <0x3c>;
			pinctrl-1 = <0x3d>;
			pinctrl-2 = <0x3e>;
			pinctrl-3 = <0x3f>;
			pinctrl-4 = <0x40>;
			pinctrl-5 = <0x41>;
			pinctrl-6 = <0x42>;
			pinctrl-7 = <0x43>;
			pinctrl-8 = <0x44>;
			pinctrl-9 = <0x45>;
			pinctrl-10 = <0x46>;
		};

		kd_camera_hw2@15008000 {
			compatible = "mediatek,camera_hw2";
			reg = <0x15008000 0x1000>;
		};

		SENINF_TOP@0x15008000 {
			compatible = "mediatek,SENINF_TOP";
			reg = <0x15008000 0x1000>;
			interrupts = <0x0 0xb6 0x8>;
		};

		fdvt@1500b000 {
			compatible = "mediatek,fdvt";
			reg = <0x1500b000 0x1000>;
			interrupts = <0x0 0xd0 0x8>;
			clocks = <0x2d 0x4 0x2d 0x6 0x29 0x1 0x37 0x8>;
			clock-names = "FD-SCP_SYS_DIS", "FD-SCP_SYS_ISP", "FD-MM_DISP0_SMI_COMMON", "FD-IMG_IMAGE_FD";
		};

		mmsys_config@14000000 {
			compatible = "mediatek,mmsys_config";
			reg = <0x14000000 0x1000>;
			interrupts = <0x0 0xcd 0x8>;
		};

		mdp_rdma@14001000 {
			compatible = "mediatek,mdp_rdma";
			reg = <0x14001000 0x1000>;
			interrupts = <0x0 0xbb 0x8>;
		};

		mdp_rsz0@14002000 {
			compatible = "mediatek,mdp_rsz0";
			reg = <0x14002000 0x1000>;
			interrupts = <0x0 0xbc 0x8>;
		};

		mdp_rsz1@14003000 {
			compatible = "mediatek,mdp_rsz1";
			reg = <0x14003000 0x1000>;
			interrupts = <0x0 0xbd 0x8>;
		};

		mdp_wdma@14004000 {
			compatible = "mediatek,mdp_wdma";
			reg = <0x14004000 0x1000>;
			interrupts = <0x0 0xbf 0x8>;
		};

		mdp_wrot@14005000 {
			compatible = "mediatek,mdp_wrot";
			reg = <0x14005000 0x1000>;
			interrupts = <0x0 0xc0 0x8>;
		};

		mdp_tdshp@14006000 {
			compatible = "mediatek,mdp_tdshp";
			reg = <0x14006000 0x1000>;
			interrupts = <0x0 0xbe 0x8>;
		};

		hacc@10008000 {
			compatible = "mediatek,hacc";
			reg = <0x10008000 0x1000>;
			interrupts = <0x0 0xae 0x8>;
		};

		als {
			compatible = "mediatek, als-eint";
		};

		gse_1 {
			compatible = "mediatek, gse_1-eint";
			status = "okay";
			interrupt-parent = <0xb>;
			interrupts = <0x42 0x8>;
			debounce = <0x42 0x0>;
		};

		ext_buck_oc {
			compatible = "mediatek, ext_buck_oc-eint";
			status = "disabled";
		};

		ext_buck {
			compatible = "mediatek, ext_buck";
			status = "okay";
		};

		swtp {
			compatible = "mediatek, swtp-eint";
		};

		dsi_te {
			compatible = "mediatek, dsi_te_1-eint";
			status = "disabled";
		};
	};

	vcorefs {
		compatible = "mediatek,mt6735-vcorefs";
		clocks = <0x2c 0x1 0x2c 0x30 0x2c 0x33>;
		clock-names = "mux_axi", "syspll_d5", "syspll1_d4";
	};

	bus {
		compatible = "simple-bus";
		#address-cells = <0x1>;
		#size-cells = <0x1>;
		ranges = <0x0 0x0 0x0 0xffffffff>;

		eintc@10005000 {
			compatible = "mediatek,mt-eic";
			reg = <0x10005000 0x1000>;
			interrupts = <0x0 0x99 0x4>;
			#interrupt-cells = <0x2>;
			interrupt-controller;
			mediatek,max_eint_num = <0xd5>;
			mediatek,mapping_table_entry = <0x0>;
			mediatek,max_deint_cnt = <0x4>;
			mediatek,deint_possible_irq = <0xbb 0xbc 0xbd 0xbe>;
			mediatek,debtime_setting_entry = <0xa>;
			mediatek,debtime_setting_array = <0x0 0x7d 0x1 0xfa 0x2 0x1f4 0x3 0x3e8 0x4 0x3e80 0x5 0x7d00 0x6 0xfa00 0x7 0x1f400 0x8 0x3e800 0x9 0x7d000>;
			linux,phandle = <0xb>;
			phandle = <0xb>;

			MD1_SIM1_HOT_PLUG_EINT@0 {
				compatible = "mediatek,MD1_SIM1_HOT_PLUG_EINT-eint";
				interrupts = <0x0 0x4>;
				debounce = <0x0 0x186a0>;
				dedicated = <0x0 0x0>;
				src_pin = <0x0 0x1>;
				sockettype = <0x0 0x0>;
				status = "okay";
			};

			pmic@206 {
				compatible = "mediatek, pmic-eint";
				interrupt-parent = <0xb>;
				interrupts = <0xce 0x4>;
				debounce = <0xce 0x3e8>;
			};
		};

		SLEEP@0x10006000 {
			compatible = "mediatek,SLEEP";
			reg = <0x10006000 0x1000>;
			interrupts = <0x0 0xa5 0x8 0x0 0xa6 0x8 0x0 0xa7 0x8 0x0 0xa8 0x8>;
		};

		DEVAPC_AO@10007000 {
			compatible = "mediatek,DEVAPC_AO";
			reg = <0x10007000 0x1000>;
		};

		dma@11000000 {
			compatible = "mediatek,ap_dma";
			reg = <0x11000000 0x1000>;
			interrupts = <0x0 0x72 0x8>;
		};

		i2c@11007000 {
			compatible = "mediatek,mt6753-i2c";
			cell-index = <0x0>;
			reg = <0x11007000 0x1000>;
			interrupts = <0x0 0x54 0x8 0x0 0x62 0x8>;
			def_speed = <0x64>;
			#address-cells = <0x1>;
			#size-cells = <0x0>;

			camera_main@10 {
				compatible = "mediatek,camera_main";
				reg = <0x10>;
				status = "okay";
			};

			camera_main_af@0c {
				compatible = "mediatek,camera_main_af";
				reg = <0xc>;
				status = "okay";
			};

			camera_sub@3c {
				compatible = "mediatek,camera_sub";
				reg = <0x3c>;
				status = "okay";
			};
		};

		i2c@11008000 {
			compatible = "mediatek,mt6753-i2c";
			cell-index = <0x1>;
			reg = <0x11008000 0x1000>;
			interrupts = <0x0 0x55 0x8 0x0 0x63 0x8>;
			def_speed = <0x64>;
			#address-cells = <0x1>;
			#size-cells = <0x0>;

			cap_touch@5d {
				compatible = "mediatek,cap_touch";
				reg = <0x5d>;
				status = "okay";
			};
		};

		i2c@11009000 {
			compatible = "mediatek,mt6753-i2c";
			cell-index = <0x2>;
			reg = <0x11009000 0x1000>;
			interrupts = <0x0 0x56 0x8 0x0 0x64 0x8>;
			def_speed = <0x64>;
			#address-cells = <0x1>;
			#size-cells = <0x0>;

			msensor@0d {
				compatible = "mediatek,msensor";
				reg = <0xd>;
				status = "okay";
			};

			gyro@68 {
				compatible = "mediatek,gyro";
				reg = <0x68>;
				status = "okay";
			};

			gsensor@0e {
				compatible = "mediatek,gsensor";
				reg = <0xe>;
				status = "okay";
			};

			alsps@29 {
				compatible = "mediatek,alsps";
				reg = <0x29>;
				status = "okay";
			};

			nfc@28 {
				compatible = "mediatek,nfc";
				reg = <0x28>;
				status = "okay";
			};

			strobe_main@63 {
				compatible = "mediatek,strobe_main";
				reg = <0x63>;
				status = "okay";
			};
		};

		i2c@1100f000 {
			compatible = "mediatek,mt6753-i2c";
			cell-index = <0x3>;
			reg = <0x1100f000 0x1000>;
			interrupts = <0x0 0x57 0x8 0x0 0x65 0x8>;
			def_speed = <0x64>;
			#address-cells = <0x1>;
			#size-cells = <0x0>;

			i2c_lcd_bias@3e {
				compatible = "mediatek,i2c_lcd_bias";
				reg = <0x3e>;
				status = "okay";
			};

			bq24296@6b {
				status = "okay";
				compatible = "bq24296";
				reg = <0x6b>;
			};
		};

		i2c@11012000 {
			compatible = "mediatek,mt6753-i2c";
			cell-index = <0x4>;
			reg = <0x11012000 0x1000>;
			interrupts = <0x0 0x58 0x8 0x0 0x66 0x8>;
			def_speed = <0x64>;
			#address-cells = <0x1>;
			#size-cells = <0x0>;
		};

		MCUCFG@0x10200000 {
			compatible = "mediatek,MCUCFG";
			reg = <0x10200000 0x200>;
			interrupts = <0x0 0x47 0x4>;
		};

		mcucfg@10200000 {
			compatible = "mediatek,mt6735-mcucfg";
			reg = <0x10200000 0x200>;
			interrupts = <0x0 0x47 0x4>;
		};

		INFRACFG_AO@0x10000000 {
			compatible = "mediatek,INFRACFG_AO";
			reg = <0x10000000 0x1000>;
		};

		CKSYS@0x10210000 {
			compatible = "mediatek,CKSYS";
			reg = <0x10210000 0x1000>;
		};

		PERICFG@0x10002000 {
			compatible = "mediatek,PERICFG";
			reg = <0x10002000 0x1000>;
		};

		bat_meter {
			compatible = "mediatek,bat_meter";
			r_bat_sense = <0x4>;
			r_i_sense = <0x4>;
			r_charger_1 = <0x14a>;
			r_charger_2 = <0x27>;
			temperature_t0 = <0x6e>;
			temperature_t1 = <0x0>;
			temperature_t2 = <0x19>;
			temperature_t3 = <0x32>;
			temperature_t = <0xff>;
			fg_meter_resistance = <0x0>;
			q_max_pos_50 = <0x1f22>;
			q_max_pos_25 = <0x1f22>;
			q_max_pos_0 = <0x1f22>;
			q_max_neg_10 = <0x1f22>;
			q_max_pos_50_h_current = <0x1f22>;
			q_max_pos_25_h_current = <0x1f22>;
			q_max_pos_0_h_current = <0x1f22>;
			q_max_neg_10_h_current = <0x1f22>;
			oam_d5 = <0x0>;
			change_tracking_point = <0x1>;
			cust_tracking_point = <0x1>;
			cust_r_sense = <0x44>;
			cust_hw_cc = <0x0>;
			aging_tuning_value = <0x67>;
			cust_r_fg_offset = <0x0>;
			ocv_board_compesate = <0x0>;
			r_fg_board_base = <0x3e8>;
			r_fg_board_slope = <0x3e8>;
			car_tune_value = <0x64>;
			current_detect_r_fg = <0xa>;
			minerroroffset = <0x3e8>;
			fg_vbat_average_size = <0x12>;
			r_fg_value = <0xa>;
			difference_hwocv_rtc = <0x1e>;
			difference_hwocv_swocv = <0xa>;
			difference_swocv_rtc = <0xa>;
			max_swocv = <0x3>;
			difference_voltage_update = <0x14>;
			aging1_load_soc = <0x46>;
			aging1_update_soc = <0x1e>;
			batterypseudo100 = <0x5f>;
			batterypseudo1 = <0x4>;
			q_max_by_sys = <0x1>;
			q_max_sys_voltage = <0xce4>;
			shutdown_gauge0 = <0x1>;
			shutdown_gauge1_xmins = <0x1>;
			shutdown_gauge1_mins = <0x3c>;
			shutdown_system_voltage = <0xd48>;
			charge_tracking_time = <0x3c>;
			discharge_tracking_time = <0xa>;
			recharge_tolerance = <0xa>;
			cust_poweron_delta_capacity_tolrance = <0x28>;
			cust_poweron_low_capacity_tolrance = <0x5>;
			cust_poweron_max_vbat_tolrance = <0x5a>;
			cust_poweron_delta_vbat_tolrance = <0x1e>;
			cust_poweron_delta_hw_sw_ocv_capacity_tolrance = <0xa>;
			fixed_tbat_25 = <0x0>;
			vbat_remove_detection = <0x0>;
			vbat_normal_wakeup = <0xe10>;
			vbat_low_power_wakeup = <0xdac>;
			normal_wakeup_period = <0x1518>;
			low_power_wakeup_period = <0x12c>;
			close_poweroff_wakeup_period = <0x1e>;
			rbat_pull_up_r = <0x4204>;
			rbat_pull_up_volt = <0x708>;
			batt_temperature_table_num = <0x11>;
			batt_temperature_table = <0xffffffec 0x10a8d 0xfffffff1 0xd192 0xfffffff6 0xa60a 0xfffffffb 0x8464 0x0 0x6a53 0x5 0x5605 0xa 0x4606 0xf 0x3952 0x14 0x2f31 0x19 0x2710 0x1e 0x207b 0x23 0x1b24 0x28 0x16ca 0x2d 0x1335 0x32 0x1041 0x37 0xdcf 0x3c 0xbc6>;
			battery_profile_t0_num = <0x64>;
			battery_profile_t0 = <0x0 0x105a 0x1 0x104a 0x2 0x103b 0x3 0x1035 0x4 0x102f 0x5 0x1023 0x6 0x1017 0x7 0x100b 0x8 0x1006 0x9 0x1000 0xa 0xff5 0xb 0xfea 0xc 0xfdf 0xd 0xfda 0xe 0xfd5 0xf 0xfca 0x10 0xfc1 0x11 0xfb7 0x12 0xfad 0x13 0xfa9 0x14 0xfa4 0x15 0xf9b 0x16 0xf92 0x17 0xf89 0x18 0xf86 0x19 0xf82 0x1a 0xf79 0x1b 0xf71 0x1c 0xf6a 0x1d 0xf63 0x1e 0xf5f 0x1f 0xf5b 0x20 0xf53 0x21 0xf4c 0x22 0xf45 0x23 0xf41 0x24 0xf3d 0x25 0xf34 0x26 0xf2b 0x27 0xf20 0x28 0xf1b 0x29 0xf15 0x2a 0xf0b 0x2b 0xf03 0x2c 0xefc 0x2d 0xef7 0x2e 0xef4 0x2f 0xef1 0x30 0xeec 0x31 0xee8 0x32 0xee4 0x33 0xee2 0x34 0xedf 0x35 0xedb 0x36 0xed8 0x37 0xed5 0x38 0xed2 0x39 0xed1 0x3a 0xecf 0x3b 0xecc 0x3c 0xec9 0x3d 0xec7 0x3e 0xec6 0x3f 0xec4 0x40 0xec2 0x41 0xec0 0x42 0xebf 0x43 0xebe 0x44 0xebc 0x45 0xeba 0x46 0xeb7 0x47 0xeb3 0x48 0xeaf 0x49 0xeae 0x4a 0xeac 0x4b 0xea7 0x4c 0xea2 0x4d 0xe9e 0x4e 0xe9d 0x4f 0xe9b 0x50 0xe97 0x51 0xe93 0x52 0xe8d 0x53 0xe87 0x54 0xe84 0x55 0xe80 0x56 0xe7a 0x57 0xe73 0x58 0xe69 0x59 0xe67 0x5a 0xe64 0x5b 0xe60 0x5c 0xe5d 0x5d 0xe5a 0x5e 0xe57 0x5f 0xe53 0x60 0xe41 0x61 0xe14 0x62 0xdd7 0x64 0xd48>;
			battery_profile_t1_num = <0x64>;
			battery_profile_t1 = <0x0 0x105a 0x1 0x104a 0x2 0x103b 0x3 0x1035 0x4 0x102f 0x5 0x1023 0x6 0x1017 0x7 0x100b 0x8 0x1006 0x9 0x1000 0xa 0xff5 0xb 0xfea 0xc 0xfdf 0xd 0xfda 0xe 0xfd5 0xf 0xfca 0x10 0xfc1 0x11 0xfb7 0x12 0xfad 0x13 0xfa9 0x14 0xfa4 0x15 0xf9b 0x16 0xf92 0x17 0xf89 0x18 0xf86 0x19 0xf82 0x1a 0xf79 0x1b 0xf71 0x1c 0xf6a 0x1d 0xf63 0x1e 0xf5f 0x1f 0xf5b 0x20 0xf53 0x21 0xf4c 0x22 0xf45 0x23 0xf41 0x24 0xf3d 0x25 0xf34 0x26 0xf2b 0x27 0xf20 0x28 0xf1b 0x29 0xf15 0x2a 0xf0b 0x2b 0xf03 0x2c 0xefc 0x2d 0xef7 0x2e 0xef4 0x2f 0xef1 0x30 0xeec 0x31 0xee8 0x32 0xee4 0x33 0xee2 0x34 0xedf 0x35 0xedb 0x36 0xed8 0x37 0xed5 0x38 0xed2 0x39 0xed1 0x3a 0xecf 0x3b 0xecc 0x3c 0xec9 0x3d 0xec7 0x3e 0xec6 0x3f 0xec4 0x40 0xec2 0x41 0xec0 0x42 0xebf 0x43 0xebe 0x44 0xebc 0x45 0xeba 0x46 0xeb7 0x47 0xeb3 0x48 0xeaf 0x49 0xeae 0x4a 0xeac 0x4b 0xea7 0x4c 0xea2 0x4d 0xe9e 0x4e 0xe9d 0x4f 0xe9b 0x50 0xe97 0x51 0xe93 0x52 0xe8d 0x53 0xe87 0x54 0xe84 0x55 0xe80 0x56 0xe7a 0x57 0xe73 0x58 0xe69 0x59 0xe67 0x5a 0xe64 0x5b 0xe60 0x5c 0xe5d 0x5d 0xe5a 0x5e 0xe57 0x5f 0xe53 0x60 0xe41 0x61 0xe14 0x62 0xdd7 0x64 0xd48>;
			battery_profile_t2_num = <0x64>;
			battery_profile_t2 = <0x0 0x105a 0x1 0x104a 0x2 0x103b 0x3 0x1035 0x4 0x102f 0x5 0x1023 0x6 0x1017 0x7 0x100b 0x8 0x1006 0x9 0x1000 0xa 0xff5 0xb 0xfea 0xc 0xfdf 0xd 0xfda 0xe 0xfd5 0xf 0xfca 0x10 0xfc1 0x11 0xfb7 0x12 0xfad 0x13 0xfa9 0x14 0xfa4 0x15 0xf9b 0x16 0xf92 0x17 0xf89 0x18 0xf86 0x19 0xf82 0x1a 0xf79 0x1b 0xf71 0x1c 0xf6a 0x1d 0xf63 0x1e 0xf5f 0x1f 0xf5b 0x20 0xf53 0x21 0xf4c 0x22 0xf45 0x23 0xf41 0x24 0xf3d 0x25 0xf34 0x26 0xf2b 0x27 0xf20 0x28 0xf1b 0x29 0xf15 0x2a 0xf0b 0x2b 0xf03 0x2c 0xefc 0x2d 0xef7 0x2e 0xef4 0x2f 0xef1 0x30 0xeec 0x31 0xee8 0x32 0xee4 0x33 0xee2 0x34 0xedf 0x35 0xedb 0x36 0xed8 0x37 0xed5 0x38 0xed2 0x39 0xed1 0x3a 0xecf 0x3b 0xecc 0x3c 0xec9 0x3d 0xec7 0x3e 0xec6 0x3f 0xec4 0x40 0xec2 0x41 0xec0 0x42 0xebf 0x43 0xebe 0x44 0xebc 0x45 0xeba 0x46 0xeb7 0x47 0xeb3 0x48 0xeaf 0x49 0xeae 0x4a 0xeac 0x4b 0xea7 0x4c 0xea2 0x4d 0xe9e 0x4e 0xe9d 0x4f 0xe9b 0x50 0xe97 0x51 0xe93 0x52 0xe8d 0x53 0xe87 0x54 0xe84 0x55 0xe80 0x56 0xe7a 0x57 0xe73 0x58 0xe69 0x59 0xe67 0x5a 0xe64 0x5b 0xe60 0x5c 0xe5d 0x5d 0xe5a 0x5e 0xe57 0x5f 0xe53 0x60 0xe41 0x61 0xe14 0x62 0xdd7 0x64 0xd48>;
			battery_profile_t3_num = <0x64>;
			battery_profile_t3 = <0x0 0x105a 0x1 0x104a 0x2 0x103b 0x3 0x1035 0x4 0x102f 0x5 0x1023 0x6 0x1017 0x7 0x100b 0x8 0x1006 0x9 0x1000 0xa 0xff5 0xb 0xfea 0xc 0xfdf 0xd 0xfda 0xe 0xfd5 0xf 0xfca 0x10 0xfc1 0x11 0xfb7 0x12 0xfad 0x13 0xfa9 0x14 0xfa4 0x15 0xf9b 0x16 0xf92 0x17 0xf89 0x18 0xf86 0x19 0xf82 0x1a 0xf79 0x1b 0xf71 0x1c 0xf6a 0x1d 0xf63 0x1e 0xf5f 0x1f 0xf5b 0x20 0xf53 0x21 0xf4c 0x22 0xf45 0x23 0xf41 0x24 0xf3d 0x25 0xf34 0x26 0xf2b 0x27 0xf20 0x28 0xf1b 0x29 0xf15 0x2a 0xf0b 0x2b 0xf03 0x2c 0xefc 0x2d 0xef7 0x2e 0xef4 0x2f 0xef1 0x30 0xeec 0x31 0xee8 0x32 0xee4 0x33 0xee2 0x34 0xedf 0x35 0xedb 0x36 0xed8 0x37 0xed5 0x38 0xed2 0x39 0xed1 0x3a 0xecf 0x3b 0xecc 0x3c 0xec9 0x3d 0xec7 0x3e 0xec6 0x3f 0xec4 0x40 0xec2 0x41 0xec0 0x42 0xebf 0x43 0xebe 0x44 0xebc 0x45 0xeba 0x46 0xeb7 0x47 0xeb3 0x48 0xeaf 0x49 0xeae 0x4a 0xeac 0x4b 0xea7 0x4c 0xea2 0x4d 0xe9e 0x4e 0xe9d 0x4f 0xe9b 0x50 0xe97 0x51 0xe93 0x52 0xe8d 0x53 0xe87 0x54 0xe84 0x55 0xe80 0x56 0xe7a 0x57 0xe73 0x58 0xe69 0x59 0xe67 0x5a 0xe64 0x5b 0xe60 0x5c 0xe5d 0x5d 0xe5a 0x5e 0xe57 0x5f 0xe53 0x60 0xe41 0x61 0xe14 0x62 0xdd7 0x64 0xd48>;
			r_profile_t0_num = <0x64>;
			r_profile_t0 = <0x7b 0x105a 0x7b 0x104a 0x7b 0x103b 0x7b 0x1035 0x7b 0x102f 0x7d 0x1023 0x7d 0x1017 0x7d 0x100b 0x7d 0x1006 0x7d 0x1000 0x7d 0xff5 0x7d 0xfea 0x7d 0xfdf 0x7d 0xfda 0x7d 0xfd5 0x7d 0xfca 0x7f 0xfc1 0x7f 0xfb7 0x7f 0xfad 0x7f 0xfa9 0x80 0xfa4 0x80 0xf9b 0x80 0xf92 0x82 0xf89 0x83 0xf86 0x84 0xf82 0x84 0xf79 0x84 0xf71 0x87 0xf6a 0x89 0xf63 0x89 0xf5f 0x89 0xf5b 0x8a 0xf53 0x8c 0xf4c 0x8c 0xf45 0x8d 0xf41 0x8e 0xf3d 0x8c 0xf34 0x8c 0xf2b 0x89 0xf20 0x87 0xf1b 0x85 0xf15 0x80 0xf0b 0x80 0xf03 0x7f 0xefc 0x7f 0xef7 0x7e 0xef4 0x7d 0xef1 0x7d 0xeec 0x7f 0xee8 0x7f 0xee4 0x7e 0xee2 0x7d 0xedf 0x7d 0xedb 0x7f 0xed8 0x7f 0xed5 0x80 0xed2 0x81 0xed1 0x82 0xecf 0x80 0xecc 0x80 0xec9 0x82 0xec7 0x82 0xec6 0x82 0xec4 0x82 0xec2 0x84 0xec0 0x85 0xebf 0x85 0xebe 0x85 0xebc 0x85 0xeba 0x84 0xeb7 0x82 0xeb3 0x80 0xeaf 0x81 0xeae 0x82 0xeac 0x80 0xea7 0x80 0xea2 0x80 0xe9e 0x81 0xe9d 0x82 0xe9b 0x82 0xe97 0x84 0xe93 0x84 0xe8d 0x84 0xe87 0x84 0xe84 0x84 0xe80 0x84 0xe7a 0x85 0xe73 0x84 0xe69 0x85 0xe67 0x87 0xe64 0x85 0xe60 0x89 0xe5d 0x8e 0xe5a 0x8f 0xe57 0x91 0xe53 0x94 0xe41 0x94 0xe14 0x9d 0xdd7 0xb1 0xd48>;
			r_profile_t1_num = <0x64>;
			r_profile_t1 = <0x7b 0x105a 0x7b 0x104a 0x7b 0x103b 0x7b 0x1035 0x7b 0x102f 0x7d 0x1023 0x7d 0x1017 0x7d 0x100b 0x7d 0x1006 0x7d 0x1000 0x7d 0xff5 0x7d 0xfea 0x7d 0xfdf 0x7d 0xfda 0x7d 0xfd5 0x7d 0xfca 0x7f 0xfc1 0x7f 0xfb7 0x7f 0xfad 0x7f 0xfa9 0x80 0xfa4 0x80 0xf9b 0x80 0xf92 0x82 0xf89 0x83 0xf86 0x84 0xf82 0x84 0xf79 0x84 0xf71 0x87 0xf6a 0x89 0xf63 0x89 0xf5f 0x89 0xf5b 0x8a 0xf53 0x8c 0xf4c 0x8c 0xf45 0x8d 0xf41 0x8e 0xf3d 0x8c 0xf34 0x8c 0xf2b 0x89 0xf20 0x87 0xf1b 0x85 0xf15 0x80 0xf0b 0x80 0xf03 0x7f 0xefc 0x7f 0xef7 0x7e 0xef4 0x7d 0xef1 0x7d 0xeec 0x7f 0xee8 0x7f 0xee4 0x7e 0xee2 0x7d 0xedf 0x7d 0xedb 0x7f 0xed8 0x7f 0xed5 0x80 0xed2 0x81 0xed1 0x82 0xecf 0x80 0xecc 0x80 0xec9 0x82 0xec7 0x82 0xec6 0x82 0xec4 0x82 0xec2 0x84 0xec0 0x85 0xebf 0x85 0xebe 0x85 0xebc 0x85 0xeba 0x84 0xeb7 0x82 0xeb3 0x80 0xeaf 0x81 0xeae 0x82 0xeac 0x80 0xea7 0x80 0xea2 0x80 0xe9e 0x81 0xe9d 0x82 0xe9b 0x82 0xe97 0x84 0xe93 0x84 0xe8d 0x84 0xe87 0x84 0xe84 0x84 0xe80 0x84 0xe7a 0x85 0xe73 0x84 0xe69 0x85 0xe67 0x87 0xe64 0x85 0xe60 0x89 0xe5d 0x8e 0xe5a 0x8f 0xe57 0x91 0xe53 0x94 0xe41 0x94 0xe14 0x9d 0xdd7 0xb1 0xd48>;
			r_profile_t2_num = <0x64>;
			r_profile_t2 = <0x7b 0x105a 0x7b 0x104a 0x7b 0x103b 0x7b 0x1035 0x7b 0x102f 0x7d 0x1023 0x7d 0x1017 0x7d 0x100b 0x7d 0x1006 0x7d 0x1000 0x7d 0xff5 0x7d 0xfea 0x7d 0xfdf 0x7d 0xfda 0x7d 0xfd5 0x7d 0xfca 0x7f 0xfc1 0x7f 0xfb7 0x7f 0xfad 0x7f 0xfa9 0x80 0xfa4 0x80 0xf9b 0x80 0xf92 0x82 0xf89 0x83 0xf86 0x84 0xf82 0x84 0xf79 0x84 0xf71 0x87 0xf6a 0x89 0xf63 0x89 0xf5f 0x89 0xf5b 0x8a 0xf53 0x8c 0xf4c 0x8c 0xf45 0x8d 0xf41 0x8e 0xf3d 0x8c 0xf34 0x8c 0xf2b 0x89 0xf20 0x87 0xf1b 0x85 0xf15 0x80 0xf0b 0x80 0xf03 0x7f 0xefc 0x7f 0xef7 0x7e 0xef4 0x7d 0xef1 0x7d 0xeec 0x7f 0xee8 0x7f 0xee4 0x7e 0xee2 0x7d 0xedf 0x7d 0xedb 0x7f 0xed8 0x7f 0xed5 0x80 0xed2 0x81 0xed1 0x82 0xecf 0x80 0xecc 0x80 0xec9 0x82 0xec7 0x82 0xec6 0x82 0xec4 0x82 0xec2 0x84 0xec0 0x85 0xebf 0x85 0xebe 0x85 0xebc 0x85 0xeba 0x84 0xeb7 0x82 0xeb3 0x80 0xeaf 0x81 0xeae 0x82 0xeac 0x80 0xea7 0x80 0xea2 0x80 0xe9e 0x81 0xe9d 0x82 0xe9b 0x82 0xe97 0x84 0xe93 0x84 0xe8d 0x84 0xe87 0x84 0xe84 0x84 0xe80 0x84 0xe7a 0x85 0xe73 0x84 0xe69 0x85 0xe67 0x87 0xe64 0x85 0xe60 0x89 0xe5d 0x8e 0xe5a 0x8f 0xe57 0x91 0xe53 0x94 0xe41 0x94 0xe14 0x9d 0xdd7 0xb1 0xd48>;
			r_profile_t3_num = <0x64>;
			r_profile_t3 = <0x7b 0x105a 0x7b 0x104a 0x7b 0x103b 0x7b 0x1035 0x7b 0x102f 0x7d 0x1023 0x7d 0x1017 0x7d 0x100b 0x7d 0x1006 0x7d 0x1000 0x7d 0xff5 0x7d 0xfea 0x7d 0xfdf 0x7d 0xfda 0x7d 0xfd5 0x7d 0xfca 0x7f 0xfc1 0x7f 0xfb7 0x7f 0xfad 0x7f 0xfa9 0x80 0xfa4 0x80 0xf9b 0x80 0xf92 0x82 0xf89 0x83 0xf86 0x84 0xf82 0x84 0xf79 0x84 0xf71 0x87 0xf6a 0x89 0xf63 0x89 0xf5f 0x89 0xf5b 0x8a 0xf53 0x8c 0xf4c 0x8c 0xf45 0x8d 0xf41 0x8e 0xf3d 0x8c 0xf34 0x8c 0xf2b 0x89 0xf20 0x87 0xf1b 0x85 0xf15 0x80 0xf0b 0x80 0xf03 0x7f 0xefc 0x7f 0xef7 0x7e 0xef4 0x7d 0xef1 0x7d 0xeec 0x7f 0xee8 0x7f 0xee4 0x7e 0xee2 0x7d 0xedf 0x7d 0xedb 0x7f 0xed8 0x7f 0xed5 0x80 0xed2 0x81 0xed1 0x82 0xecf 0x80 0xecc 0x80 0xec9 0x82 0xec7 0x82 0xec6 0x82 0xec4 0x82 0xec2 0x84 0xec0 0x85 0xebf 0x85 0xebe 0x85 0xebc 0x85 0xeba 0x84 0xeb7 0x82 0xeb3 0x80 0xeaf 0x81 0xeae 0x82 0xeac 0x80 0xea7 0x80 0xea2 0x80 0xe9e 0x81 0xe9d 0x82 0xe9b 0x82 0xe97 0x84 0xe93 0x84 0xe8d 0x84 0xe87 0x84 0xe84 0x84 0xe80 0x84 0xe7a 0x85 0xe73 0x84 0xe69 0x85 0xe67 0x87 0xe64 0x85 0xe60 0x89 0xe5d 0x8e 0xe5a 0x8f 0xe57 0x91 0xe53 0x94 0xe41 0x94 0xe14 0x9d 0xdd7 0xb1 0xd48>;
		};

		bat_notify {
			compatible = "mediatek,bat_notify";
		};

		bat_comm {
			compatible = "mediatek,battery";
			usb_charger_current = <0xea60>;
			ac_charger_input_current = <0x320c8>;
			ac_charger_current = <0x320c8>;
			non_std_ac_charger_current = <0xea60>;
			charging_host_charger_current = <0xea60>;
			bat_low_temp_protect_enable = <0x1>;
			v_charger_enable = <0x0>;
			v_charger_max = <0x1964>;
			v_charger_min = <0x1130>;
			max_charge_temperature = <0x32>;
			min_charge_temperature = <0xfffffffb>;
			max_charge_temperature_minus_x_degree = <0x2f>;
			min_charge_temperature_plus_x_degree = <0x6>;
			onehundred_percent_tracking_time = <0xa>;
			npercent_tracking_time = <0x14>;
			sync_to_real_tracking_time = <0x3c>;
			v_0percent_tracking = <0xd48>;
			high_battery_voltage_support = <0x0>;
		};

		FHCTL@0x10209F00 {
			compatible = "mediatek,FHCTL";
			reg = <0x10209f00 0x100>;
		};

		gcpu@10216000 {
			compatible = "mediatek,gcpu";
			reg = <0x10216000 0x1000>;
			interrupts = <0x0 0x96 0x8>;
		};

		cqdma@10217c00 {
			compatible = "mediatek,cqdma";
			reg = <0x10217c00 0xc00>;
			interrupts = <0x0 0x8f 0x8>;
			nr_channel = <0x1>;
		};

		EMI@0x10203000 {
			compatible = "mediatek,EMI";
			reg = <0x10203000 0x1000>;
			interrupts = <0x0 0x88 0x4>;
		};

		m4u@10205000 {
			cell-index = <0x0>;
			compatible = "mediatek,m4u";
			reg = <0x10205000 0x1000>;
			interrupts = <0x0 0x92 0x8>;
			clocks = <0x16 0x9 0x29 0x1 0x29 0x2 0x2a 0x1 0x2a 0x2 0x37 0x1 0x2b 0x2 0x2b 0x1>;
			clock-names = "infra_m4u", "smi_common", "m4u_disp0_smi_larb0", "m4u_vdec0_vdec", "m4u_vdec1_larb", "m4u_img_image_larb2_smi", "m4u_venc_venc", "m4u_venc_larb";
		};

		ccci_off@0 {
			compatible = "mediatek,ccci_off";
			clocks = <0x2d 0x1>;
			clock-names = "scp-sys-md1-main";
		};

		mdcldma@1000A000 {
			compatible = "mediatek,mdcldma";
			reg = <0x1000a000 0x1000 0x1000b000 0x1000 0x1021a000 0x1000 0x1021b000 0x1000 0x1020a000 0x1000 0x1020b000 0x1000>;
			interrupts = <0x0 0x91 0x4 0x0 0x8c 0x8 0x0 0xdf 0x2>;
			mediatek,md_id = <0x0>;
			mediatek,cldma_capability = <0x2>;
			mediatek,md_smem_size = <0x10000>;
			pinctrl-names = "default", "vsram_output_low", "vsram_output_high", "RFIC0_01_mode", "RFIC0_04_mode";
			pinctrl-0 = <0x47>;
			pinctrl-1 = <0x48>;
			pinctrl-2 = <0x49>;
			pinctrl-3 = <0x4a>;
			pinctrl-4 = <0x4b>;
		};

		mdc2k@3a00b01c {
			compatible = "mediatek,mdc2k";
			reg = <0x3a00b01c 0x10 0x1021c800 0x300 0x1021d800 0x300>;
			interrupts = <0x0 0xdd 0x2>;
			clocks = <0x2d 0x2>;
			clock-names = "scp-sys-md2-main";
		};

		c2k_sdio@0 {
			compatible = "mediatek,mt6735-c2k_sdio";
			interrupts = <0x0 0xde 0x8>;
		};

		dbgapb_base@1011A000 {
			compatible = "mediatek,dbgapb_base";
			reg = <0x1011a000 0x100>;
		};

		simswitch@0 {
			compatible = "mediatek,sim_switch";
			pinctrl-names = "default", "hot_plug_mode1", "hot_plug_mode2", "two_sims_bound_to_md1", "sim1_md3_sim2_md1";
			pinctrl-0 = <0x4c>;
			pinctrl-1 = <0x4d>;
			pinctrl-2 = <0x4e>;
			pinctrl-3 = <0x4f>;
			pinctrl-4 = <0x50>;
		};

		EFUSEC@10206000 {
			compatible = "mediatek,EFUSEC";
			reg = <0x10206000 0x1000>;
		};

		DEVAPC@10207000 {
			compatible = "mediatek,DEVAPC";
			reg = <0x10207000 0x1000>;
			interrupts = <0x0 0x86 0x8>;
		};

		bus_dbg@10208000 {
			compatible = "mediatek,bus_dbg-v1";
			reg = <0x10208000 0x1000>;
			interrupts = <0x0 0x89 0x8>;
		};

		APMIXED@0x10209000 {
			compatible = "mediatek,APMIXED";
			reg = <0x10209000 0x1000>;
		};

		dispsys@14007000 {
			compatible = "mediatek,dispsys";
			reg = <0x14007000 0x1000 0x14008000 0x1000 0x14009000 0x1000 0x1400a000 0x1000 0x1400b000 0x1000 0x1400c000 0x1000 0x1400d000 0x1000 0x1400e000 0x1000 0x1400f000 0x1000 0x14010000 0x1000 0x0 0x0 0x1100e000 0x1000 0x0 0x0 0x14015000 0x1000 0x14013000 0x1000 0x14014000 0x1000 0x14000000 0x1000 0x14016000 0x1000 0x14017000 0x1000 0x14018000 0x1000 0x10206000 0x1000 0x10210000 0x1000 0x10211a70 0xc 0x10211974 0xc 0x10211b70 0xc 0x10206044 0xc 0x10206514 0xc 0x10206558 0xc 0x102100a0 0x1000 0x10209260 0x1000 0x10209264 0x1000 0x14012000 0x1000 0x10209000 0x1000>;
			interrupts = <0x0 0xc1 0x8 0x0 0xd3 0x8 0x0 0xc2 0x8 0x0 0xc3 0x8 0x0 0xc4 0x8 0x0 0xc5 0x8 0x0 0xc6 0x8 0x0 0xc7 0x8 0x0 0xc8 0x8 0x0 0xc9 0x8 0x0 0x0 0x8 0x0 0x75 0x8 0x0 0x0 0x8 0x0 0xba 0x8 0x0 0xcb 0x8 0x0 0xcc 0x8 0x0 0xcd 0x8 0x0 0xb0 0x8 0x0 0x0 0x8 0x0 0x0 0x8 0x0 0x0 0x8 0x0 0x0 0x8 0x0 0x0 0x8 0x0 0x0 0x8 0x0 0x0 0x8 0x0 0x0 0x8 0x0 0x0 0x8 0x0 0x0 0x8 0x0 0x0 0x8 0x0 0x0 0x8 0x0 0x0 0x8 0x0 0xd2 0x8 0x0 0x0 0x8>;
		};

		mhl@0 {
			compatible = "mediatek,extd_dev";
		};

		lcm {
			compatible = "mediatek,mt6753p1_64-lcm";
			gpio_lcm_pwr_en = <0x9 0x39 0x0>;
			gpio_lcm_rst_en = <0x9 0x92 0x0>;
			lcm_bl_gpio = <0x9 0x3 0x0>;
			lcm_bias_enp_gpio = <0x9 0x3a 0x0>;
			lcm_id_gpio = <0x9 0x13 0x0>;
		};

		lcm_mode {
			compatible = "mediatek,lcm_mode";
			pinctrl-names = "default", "lcm_mode_00", "lcm_mode_01", "lcm_mode_02", "lcm_mode_03", "lcm_mode_04", "lcm_mode_05", "lcm_mode_06", "lcm_mode_07";
			pinctrl-0 = <0x51>;
			pinctrl-1 = <0x52>;
			pinctrl-2 = <0x53>;
			pinctrl-3 = <0x54>;
			pinctrl-4 = <0x55>;
			pinctrl-5 = <0x56>;
			pinctrl-6 = <0x57>;
			pinctrl-7 = <0x58>;
			pinctrl-8 = <0x59>;
			lcm_power_gpio = <0x9 0x50 0x0>;
			lcm_bl_gpio = <0x9 0x81 0x0>;
			status = "okay";
		};

		cpu_dbgapb {
			compatible = "mediatek,hw_dbg";
			num = <0x8>;
			reg = <0x10810000 0x1000 0x10910000 0x1000 0x10a10000 0x1000 0x10b10000 0x1000 0x10c10000 0x1000 0x10d10000 0x1000 0x10e10000 0x1000 0x10f10000 0x1000>;
		};

		syscfg_pctl_a {
			compatible = "mediatek,mt6735-pctl-a-syscfg", "syscon";
			reg = <0x0 0x9bceb8 0x0 0x3e8>;
			linux,phandle = <0x5a>;
			phandle = <0x5a>;
		};

		pinctrl {
			compatible = "mediatek,mt6735-pinctrl";
			reg = <0x0 0x9bceb8 0x0 0x3e8>;
			mediatek,pctl-regmap = <0x5a>;
			pins-are-numbered;
			gpio-controller;
			#gpio-cells = <0x2>;
			linux,phandle = <0x9>;
			phandle = <0x9>;

			uart0gpiodefault {
				linux,phandle = <0x2e>;
				phandle = <0x2e>;

				pins_cmd_dat {
					pinmux = <0x4a01>;
					slew-rate = <0x0>;
					bias-pull-up;
				};
			};

			uart0_rx_set {
				linux,phandle = <0x2f>;
				phandle = <0x2f>;

				pins_cmd_dat {
					pinmux = <0x4a01>;
					slew-rate = <0x0>;
					bias-pull-up;
				};
			};

			uart0_rx_clear {
				linux,phandle = <0x30>;
				phandle = <0x30>;

				pins_cmd_dat {
					pinmux = <0x4a00>;
					slew-rate = <0x1>;
					output-high;
				};
			};

			uart0_tx_set {
				linux,phandle = <0x31>;
				phandle = <0x31>;

				pins_cmd_dat {
					pinmux = <0x4b01>;
				};
			};

			uart0_tx_clear {
				linux,phandle = <0x32>;
				phandle = <0x32>;

				pins_cmd_dat {
					pinmux = <0x4b00>;
					slew-rate = <0x1>;
					output-high;
				};
			};

			uart1gpiodefault {
			};

			uart1_rx_set {

				pins_cmd_dat {
					pinmux = <0x4c01>;
				};
			};

			uart1_rx_clear {

				pins_cmd_dat {
					pinmux = <0x4c00>;
					slew-rate = <0x1>;
					output-high;
				};
			};

			uart1_tx_set {

				pins_cmd_dat {
					pinmux = <0x4d01>;
				};
			};

			uart1_tx_clear {

				pins_cmd_dat {
					pinmux = <0x4d00>;
					slew-rate = <0x1>;
					output-high;
				};
			};

			uart2gpiodefault {
			};

			uart2_rx_set {

				pins_cmd_dat {
					pinmux = <0x3901>;
				};
			};

			uart2_rx_clear {

				pins_cmd_dat {
					pinmux = <0x3900>;
					slew-rate = <0x1>;
					output-high;
				};
			};

			uart2_tx_set {

				pins_cmd_dat {
					pins = <0x3a01>;
				};
			};

			uart2_tx_clear {

				pins_cmd_dat {
					pinmux = <0x3a00>;
					slew-rate = <0x1>;
					output-high;
				};
			};

			uart3gpiodefault {
			};

			uart3_rx_set {

				pins_cmd_dat {
					pinmux = <0x3b01>;
				};
			};

			uart3_rx_clear {

				pins_cmd_dat {
					pinmux = <0x3b00>;
					slew-rate = <0x1>;
					output-high;
				};
			};

			uart3_tx_set {

				pins_cmd_dat {
					pinmux = <0x3c01>;
				};
			};

			uart3_tx_clear {

				pins_cmd_dat {
					pinmux = <0x3c00>;
					slew-rate = <0x1>;
					output-high;
				};
			};

			ssw0default {
				linux,phandle = <0x4c>;
				phandle = <0x4c>;
			};

			ssw@1 {
				linux,phandle = <0x4d>;
				phandle = <0x4d>;

				pins_cmd0_dat {
					pins = <0x805>;
				};

				pins_cmd1_dat {
					pins = <0x904>;
				};
			};

			ssw@2 {
				linux,phandle = <0x4e>;
				phandle = <0x4e>;

				pins_cmd0_dat {
					pins = <0x802>;
				};

				pins_cmd1_dat {
					pins = <0x904>;
				};
			};

			ssw@3 {
				linux,phandle = <0x4f>;
				phandle = <0x4f>;

				pins_cmd0_dat {
					pins = <0xa301>;
					slew-rate = <0x1>;
				};

				pins_cmd1_dat {
					pins = <0xa401>;
					slew-rate = <0x1>;
				};

				pins_cmd2_dat {
					pins = <0xa501>;
					slew-rate = <0x0>;
					bias-pull-up = <0x0>;
				};

				pins_cmd3_dat {
					pins = <0xa001>;
					slew-rate = <0x1>;
				};

				pins_cmd4_dat {
					pins = <0xa101>;
					slew-rate = <0x1>;
				};

				pins_cmd5_dat {
					pins = <0xa201>;
					slew-rate = <0x0>;
					bias-pull-up = <0x0>;
				};
			};

			ssw@4 {
				linux,phandle = <0x50>;
				phandle = <0x50>;

				pins_cmd0_dat {
					pins = <0xa304>;
				};

				pins_cmd1_dat {
					pins = <0xa404>;
				};

				pins_cmd2_dat {
					pins = <0xa504>;
				};

				pins_cmd3_dat {
					pins = <0xa001>;
				};

				pins_cmd4_dat {
					pins = <0xa101>;
				};

				pins_cmd5_dat {
					pins = <0xa201>;
				};
			};

			vsram0default {
				linux,phandle = <0x47>;
				phandle = <0x47>;
			};

			vsram@1 {
				linux,phandle = <0x48>;
				phandle = <0x48>;

				pins_cmd_dat {
					pins = <0x8c00>;
					slew-rate = <0x1>;
					output-low;
				};
			};

			vsram@2 {
				linux,phandle = <0x49>;
				phandle = <0x49>;

				pins_cmd_dat {
					pins = <0x8c00>;
					slew-rate = <0x1>;
					output-high;
				};
			};

			clockbuf@1 {
				linux,phandle = <0x4a>;
				phandle = <0x4a>;

				pins_cmd0_dat {
					pins = <0x6e01>;
				};

				pins_cmd1_dat {
					pins = <0x6f01>;
				};

				pins_cmd2_dat {
					pins = <0x7001>;
				};

				pins_cmd3_dat {
					pins = <0x7101>;
				};

				pins_cmd4_dat {
					pins = <0x7201>;
				};
			};

			clockbuf@2 {
				linux,phandle = <0x4b>;
				phandle = <0x4b>;

				pins_cmd0_dat {
					pins = <0x6e04>;
				};

				pins_cmd1_dat {
					pins = <0x6f04>;
				};

				pins_cmd2_dat {
					pins = <0x7004>;
				};

				pins_cmd3_dat {
					pins = <0x7104>;
				};

				pins_cmd4_dat {
					pins = <0x7204>;
				};
			};

			eint0default {
				linux,phandle = <0x72>;
				phandle = <0x72>;
			};

			eint86default {
				linux,phandle = <0x78>;
				phandle = <0x78>;
			};

			eint86 {
				linux,phandle = <0x79>;
				phandle = <0x79>;

				pins_cmd_dat {
					pins = <0x5600>;
					bias-disable;
				};
			};

			eint@0 {
				linux,phandle = <0x73>;
				phandle = <0x73>;

				pins_cmd_dat {
					pins = <0xa00>;
					slew-rate = <0x0>;
					bias-disable;
				};
			};

			eintoutput0 {
				linux,phandle = <0x74>;
				phandle = <0x74>;

				pins_cmd_dat {
					pins = <0xa00>;
					slew-rate = <0x1>;
					output-low;
				};
			};

			eintoutput1 {
				linux,phandle = <0x75>;
				phandle = <0x75>;

				pins_cmd_dat {
					pins = <0xa00>;
					slew-rate = <0x1>;
					output-high;
				};
			};

			rstoutput0 {
				linux,phandle = <0x76>;
				phandle = <0x76>;

				pins_cmd_dat {
					pins = <0x3e00>;
					slew-rate = <0x1>;
					output-low;
				};
			};

			rstoutput1 {
				linux,phandle = <0x77>;
				phandle = <0x77>;

				pins_cmd_dat {
					pins = <0x3e00>;
					slew-rate = <0x1>;
					output-high;
				};
			};

			cam0@0 {
				linux,phandle = <0x3d>;
				phandle = <0x3d>;

				pins_cmd_dat {
					pins = <0x2c00>;
					slew-rate = <0x1>;
					output-low;
				};
			};

			cam0@1 {
				linux,phandle = <0x3e>;
				phandle = <0x3e>;

				pins_cmd_dat {
					pins = <0x2c00>;
					slew-rate = <0x1>;
					output-high;
				};
			};

			cam0@2 {
				linux,phandle = <0x3f>;
				phandle = <0x3f>;

				pins_cmd_dat {
					pins = <0x5200>;
					slew-rate = <0x1>;
					output-low;
				};
			};

			cam0@3 {
				linux,phandle = <0x40>;
				phandle = <0x40>;

				pins_cmd_dat {
					pins = <0x5200>;
					slew-rate = <0x1>;
					output-high;
				};
			};

			cam1@0 {
				linux,phandle = <0x41>;
				phandle = <0x41>;

				pins_cmd_dat {
					pins = <0xb00>;
					slew-rate = <0x1>;
					output-low;
				};
			};

			cam1@1 {
				linux,phandle = <0x42>;
				phandle = <0x42>;

				pins_cmd_dat {
					pins = <0xb00>;
					slew-rate = <0x1>;
					output-high;
				};
			};

			cam1@2 {
				linux,phandle = <0x43>;
				phandle = <0x43>;

				pins_cmd_dat {
					pins = <0xc00>;
					slew-rate = <0x1>;
					output-low;
				};
			};

			cam1@3 {
				linux,phandle = <0x44>;
				phandle = <0x44>;

				pins_cmd_dat {
					pins = <0xc00>;
					slew-rate = <0x1>;
					output-high;
				};
			};

			cam@0 {
				linux,phandle = <0x45>;
				phandle = <0x45>;

				pins_cmd_dat {
					pins = <0x3f00>;
					slew-rate = <0x1>;
					output-low;
				};
			};

			cam@1 {
				linux,phandle = <0x46>;
				phandle = <0x46>;

				pins_cmd_dat {
					pins = <0x3f00>;
					slew-rate = <0x1>;
					output-high;
				};
			};

			camdefault {
				linux,phandle = <0x3c>;
				phandle = <0x3c>;
			};

			default {
				linux,phandle = <0x33>;
				phandle = <0x33>;
			};

			gpslna@0 {
				linux,phandle = <0x34>;
				phandle = <0x34>;

				pins_cmd_dat {
					pins = <0x4d00>;
					slew-rate = <0x0>;
					bias-disable;
					output-low;
				};
			};

			gpslna@1 {
				linux,phandle = <0x35>;
				phandle = <0x35>;

				pins_cmd_dat {
					pins = <0x4d00>;
					slew-rate = <0x1>;
					bias-pull-up = <0x0>;
					output-high;
				};
			};

			gpslna@2 {
				linux,phandle = <0x36>;
				phandle = <0x36>;

				pins_cmd_dat {
					pins = <0x4d00>;
					slew-rate = <0x1>;
					bias-pull-up = <0x0>;
					output-low;
				};
			};

			mmc0@default {
				linux,phandle = <0x2>;
				phandle = <0x2>;

				pins_cmd {
					drive-strength = [02];
				};

				pins_dat {
					drive-strength = [02];
				};

				pins_clk {
					drive-strength = [02];
				};

				pins_rst {
					drive-strength = [02];
				};

				pins_ds {
					drive-strength = [02];
				};
			};

			mmc0@register_default {
				dat0rddly = [00];
				dat1rddly = [00];
				dat2rddly = [00];
				dat3rddly = [00];
				dat4rddly = [00];
				dat5rddly = [00];
				dat6rddly = [00];
				dat7rddly = [00];
				datwrddly = [00];
				cmdrrddly = [00];
				cmdrddly = [00];
				cmd_edge = [01];
				rdata_edge = [01];
				wdata_edge = [01];
				ett-hs200-cells = <0xc>;
				ett-hs200-default = <0xb0 0x380 0x0 0xb0 0x7c00 0x0 0xb4 0x38 0x1 0x4 0x2 0x1 0xf0 0x1f0000 0xf 0xf0 0x7c00000 0x0 0xb4 0x7 0x1 0xf0 0x1f 0xf 0x4 0x400 0x1 0xf8 0x1f000000 0xf 0xf0 0x1f00 0x16 0x4 0x4 0x0>;
				ett-hs400-cells = <0x8>;
				ett-hs400-default = <0xb0 0x380 0x0 0xb0 0x7c00 0x0 0x188 0x7c 0x2 0x188 0x1f000 0xe 0xb4 0x38 0x1 0x4 0x2 0x0 0xf0 0x1f0000 0xf 0xf0 0x7c00000 0xd>;
				linux,phandle = <0x3>;
				phandle = <0x3>;
			};

			mmc1@default {
				linux,phandle = <0x4>;
				phandle = <0x4>;

				pins_cmd {
					drive-strength = [03];
				};

				pins_dat {
					drive-strength = [03];
				};

				pins_clk {
					drive-strength = [03];
				};
			};

			mmc1@sdr104 {
				linux,phandle = <0x5>;
				phandle = <0x5>;

				pins_cmd {
					drive-strength = [02];
				};

				pins_dat {
					drive-strength = [02];
				};

				pins_clk {
					drive-strength = [03];
				};
			};

			mmc1@sdr50 {
				linux,phandle = <0x6>;
				phandle = <0x6>;

				pins_cmd {
					drive-strength = [02];
				};

				pins_dat {
					drive-strength = [02];
				};

				pins_clk {
					drive-strength = [03];
				};
			};

			mmc1@ddr50 {
				linux,phandle = <0x7>;
				phandle = <0x7>;

				pins_cmd {
					drive-strength = [02];
				};

				pins_dat {
					drive-strength = [02];
				};

				pins_clk {
					drive-strength = [03];
				};
			};

			mmc1@register_default {
				dat0rddly = [00];
				dat1rddly = [00];
				dat2rddly = [00];
				dat3rddly = [00];
				datwrddly = [00];
				cmdrrddly = [00];
				cmdrddly = [00];
				cmd_edge = [01];
				rdata_edge = [01];
				wdata_edge = [01];
				linux,phandle = <0x8>;
				phandle = <0x8>;
			};

			state_ven_high {
				linux,phandle = <0x5b>;
				phandle = <0x5b>;

				pins_cmd_dat {
					pins = <0x400>;
					slew-rate = <0x1>;
					output-high;
				};
			};

			state_ven_low {
				linux,phandle = <0x5c>;
				phandle = <0x5c>;

				pins_cmd_dat {
					pins = <0x400>;
					slew-rate = <0x1>;
					output-low;
				};
			};

			state_rst_high {
				linux,phandle = <0x5d>;
				phandle = <0x5d>;

				pins_cmd_dat {
					pins = <0x300>;
					slew-rate = <0x1>;
					output-high;
				};
			};

			state_rst_low {
				linux,phandle = <0x5e>;
				phandle = <0x5e>;

				pins_cmd_dat {
					pins = <0x300>;
					slew-rate = <0x1>;
					output-low;
				};
			};

			state_eint_high {
				linux,phandle = <0x5f>;
				phandle = <0x5f>;

				pins_cmd_dat {
					pins = <0x100>;
					slew-rate = <0x1>;
					output-high;
				};
			};

			state_eint_low {
				linux,phandle = <0x60>;
				phandle = <0x60>;

				pins_cmd_dat {
					pins = <0x100>;
					slew-rate = <0x1>;
					output-low;
				};
			};

			state_irq_init {
				linux,phandle = <0x61>;
				phandle = <0x61>;

				pins_cmd_dat {
					pins = <0x200>;
					slew-rate = <0x0>;
					bias-pull-down = <0x0>;
				};
			};

			usb_default {
				linux,phandle = <0x63>;
				phandle = <0x63>;
			};

			iddig_irq_init {
				linux,phandle = <0x64>;
				phandle = <0x64>;

				pins_cmd_dat {
					pins = <0x4305>;
					slew-rate = <0x0>;
					bias-pull-up = <0x0>;
				};
			};

			drvvbus_init {
				linux,phandle = <0x65>;
				phandle = <0x65>;

				pins_cmd_dat {
					pins = <0x5302>;
					slew-rate = <0x1>;
					bias-pull-up = <0x0>;
				};
			};

			drvvbus_low {
				linux,phandle = <0x66>;
				phandle = <0x66>;

				pins_cmd_dat {
					pins = <0x5302>;
					slew-rate = <0x1>;
					output-low;
				};
			};

			drvvbus_high {
				linux,phandle = <0x67>;
				phandle = <0x67>;

				pins_cmd_dat {
					pins = <0x5302>;
					slew-rate = <0x1>;
					output-high;
				};
			};

			audiodefault {
				linux,phandle = <0x68>;
				phandle = <0x68>;
			};

			pmicclkmode0 {
				linux,phandle = <0x69>;
				phandle = <0x69>;

				pins_cmd0_dat {
					pins = <0x8f00>;
				};

				pins_cmd1_dat {
					pins = <0x9000>;
				};

				pins_cmd2_dat {
					pins = <0x9100>;
				};
			};

			pmicclkmode1 {
				linux,phandle = <0x6a>;
				phandle = <0x6a>;

				pins_cmd0_dat {
					pins = <0x8f01>;
				};

				pins_cmd1_dat {
					pins = <0x9001>;
				};

				pins_cmd2_dat {
					pins = <0x9101>;
				};
			};

			audi2s1mode0 {
				linux,phandle = <0x6b>;
				phandle = <0x6b>;

				pins_cmd0_dat {
					pins = <0x4e00>;
				};

				pins_cmd1_dat {
					pins = <0x4f00>;
				};

				pins_cmd2_dat {
					pins = <0x5000>;
				};
			};

			audi2s1mode1 {
				linux,phandle = <0x6c>;
				phandle = <0x6c>;

				pins_cmd0_dat {
					pins = <0x4e01>;
				};

				pins_cmd1_dat {
					pins = <0x4f01>;
				};

				pins_cmd2_dat {
					pins = <0x5001>;
				};
			};

			audexamphigh {
				linux,phandle = <0x6d>;
				phandle = <0x6d>;

				pins_cmd_dat {
					pins = <0x4000>;
					slew-rate = <0x1>;
					output-high;
				};
			};

			audexamplow {
				linux,phandle = <0x6e>;
				phandle = <0x6e>;

				pins_cmd_dat {
					pins = <0x4000>;
					slew-rate = <0x1>;
					output-low;
				};
			};

			audrcvspkhigh {
				linux,phandle = <0x6f>;
				phandle = <0x6f>;

				pins_cmd_dat {
					pins = <0x7800>;
					slew-rate = <0x1>;
					output-low;
				};
			};

			audrcvspklow {
				linux,phandle = <0x70>;
				phandle = <0x70>;

				pins_cmd_dat {
					pins = <0x7800>;
					slew-rate = <0x1>;
					output-high;
				};
			};

			lcm_mode_default {
				linux,phandle = <0x51>;
				phandle = <0x51>;

				pins_cmd_dat {
					pins = <0x5000>;
				};
			};

			lcm_mode@0 {
				linux,phandle = <0x52>;
				phandle = <0x52>;

				pins_cmd_dat {
					pins = <0x5000>;
				};
			};

			lcm_mode@1 {
				linux,phandle = <0x53>;
				phandle = <0x53>;

				pins_cmd_dat {
					pins = <0x5001>;
				};
			};

			lcm_mode@2 {
				linux,phandle = <0x54>;
				phandle = <0x54>;

				pins_cmd_dat {
					pins = <0x5002>;
				};
			};

			lcm_mode@3 {
				linux,phandle = <0x55>;
				phandle = <0x55>;

				pins_cmd_dat {
					pins = <0x5003>;
				};
			};

			lcm_mode@4 {
				linux,phandle = <0x56>;
				phandle = <0x56>;

				pins_cmd_dat {
					pins = <0x5004>;
				};
			};

			lcm_mode@5 {
				linux,phandle = <0x57>;
				phandle = <0x57>;

				pins_cmd_dat {
					pins = <0x5005>;
				};
			};

			lcm_mode@6 {
				linux,phandle = <0x58>;
				phandle = <0x58>;

				pins_cmd_dat {
					pins = <0x5006>;
				};
			};

			lcm_mode@7 {
				linux,phandle = <0x59>;
				phandle = <0x59>;

				pins_cmd_dat {
					pins = <0x5007>;
				};
			};
		};

		nfc@0 {
			compatible = "mediatek,nfc-gpio-v2";
			gpio-ven = <0x4>;
			gpio-rst = <0x3>;
			gpio-eint = <0x1>;
			gpio-irq = <0x2>;
			pinctrl-names = "default", "ven_high", "ven_low", "rst_high", "rst_low", "eint_high", "eint_low", "irq_init";
			pinctrl-0 = <0x33>;
			pinctrl-1 = <0x5b>;
			pinctrl-2 = <0x5c>;
			pinctrl-3 = <0x5d>;
			pinctrl-4 = <0x5e>;
			pinctrl-5 = <0x5f>;
			pinctrl-6 = <0x60>;
			pinctrl-7 = <0x61>;
			status = "okay";
		};

		btcvsd@10000000 {
			compatible = "mediatek,audio_bt_cvsd";
			offset = <0x700 0x800 0xfd0 0xfd4 0xfd8>;
			reg = <0x10000000 0x1000 0x18000000 0x10000 0x18080000 0x8000>;
			interrupts = <0x0 0xe6 0x8>;
		};

		gps {
			compatible = "mediatek,gps";
		};

		wifi@180F0000 {
			compatible = "mediatek,wifi";
			reg = <0x180f0000 0x5c>;
			interrupts = <0x0 0xe4 0x8>;
		};

		usb20@11200000 {
			compatible = "mediatek,mt6735-usb20";
			cell-index = <0x0>;
			reg = <0x11200000 0x10000 0x11210000 0x10000>;
			interrupts = <0x0 0x48 0x8>;
			mode = <0x2>;
			multipoint = <0x1>;
			dyn_fifo = <0x1>;
			soft_con = <0x1>;
			dma = <0x1>;
			num_eps = <0x10>;
			dma_channels = <0x8>;
			clocks = <0xa 0xb>;
			clock-names = "usb0";
			VUSB33-supply = <0x62>;
			iddig_gpio = <0x43 0x1>;
			drvvbus_gpio = <0x53 0x2>;
			pinctrl-names = "usb_default", "iddig_irq_init", "drvvbus_init", "drvvbus_low", "drvvbus_high";
			pinctrl-0 = <0x63>;
			pinctrl-1 = <0x64>;
			pinctrl-2 = <0x65>;
			pinctrl-3 = <0x66>;
			pinctrl-4 = <0x67>;
			status = "okay";
		};

		audio@11220000 {
			compatible = "mediatek,audio";
			reg = <0x11220000 0x10000>;
			interrupts = <0x0 0x90 0x8>;
		};

		mt_soc_dl1_pcm@11220000 {
			compatible = "mediatek,mt-soc-dl1-pcm";
			reg = <0x11220000 0x1000>;
			interrupts = <0x0 0x90 0x8>;
			audclk-gpio = <0x8f 0x0>;
			audmiso-gpio = <0x90 0x0>;
			audmosi-gpio = <0x91 0x0>;
			vowclk-gpio = <0x94 0x0>;
			extspkamp-gpio = <0x75 0x0>;
			i2s1clk-gpio = <0x50 0x0>;
			i2s1dat-gpio = <0x4e 0x0>;
			i2s1mclk-gpio = <0x9 0x0>;
			i2s1ws-gpio = <0x4f 0x0>;
			pinctrl-names = "default", "audpmicclk-mode0", "audpmicclk-mode1", "audi2s1-mode0", "audi2s1-mode1", "extamp-pullhigh", "extamp-pulllow", "rcvspk-pullhigh", "rcvspk-pulllow";
			pinctrl-0 = <0x68>;
			pinctrl-1 = <0x69>;
			pinctrl-2 = <0x6a>;
			pinctrl-3 = <0x6b>;
			pinctrl-4 = <0x6c>;
			pinctrl-5 = <0x6d>;
			pinctrl-6 = <0x6e>;
			pinctrl-7 = <0x6f>;
			pinctrl-8 = <0x70>;
			status = "okay";
		};

		mt_soc_ul1_pcm@11220000 {
			compatible = "mediatek,mt_soc_pcm_capture";
		};

		mt_soc_voice_md1@11220000 {
			compatible = "mediatek,mt_soc_pcm_voice_md1";
		};

		mt_soc_hdmi_pcm@11220000 {
			compatible = "mediatek,mt_soc_pcm_hdmi";
		};

		mt_soc_uldlloopback_pcm@11220000 {
			compatible = "mediatek,mt_soc_pcm_uldlloopback";
		};

		mt_soc_i2s0_pcm@11220000 {
			compatible = "mediatek,mt_soc_pcm_dl1_i2s0";
		};

		mt_soc_mrgrx_pcm@11220000 {
			compatible = "mediatek,mt_soc_pcm_mrgrx";
		};

		mt_soc_mrgrx_awb_pcm@11220000 {
			compatible = "mediatek,mt_soc_pcm_mrgrx_awb";
		};

		mt_soc_fm_i2s_pcm@11220000 {
			compatible = "mediatek,mt_soc_pcm_fm_i2s";
		};

		mt_soc_fm_i2s_awb_pcm@11220000 {
			compatible = "mediatek,mt_soc_pcm_fm_i2s_awb";
		};

		mt_soc_i2s0dl1_pcm@11220000 {
			compatible = "mediatek,mt_soc_pcm_dl1_i2s0Dl1";
		};

		mt_soc_dl1_awb_pcm@11220000 {
			compatible = "mediatek,mt_soc_pcm_dl1_awb";
		};

		mt_soc_voice_md1_bt@11220000 {
			compatible = "mediatek,mt_soc_pcm_voice_md1_bt";
		};

		mt_soc_voip_bt_out@11220000 {
			compatible = "mediatek,mt_soc_pcm_dl1_bt";
		};

		mt_soc_voip_bt_in@11220000 {
			compatible = "mediatek,mt_soc_pcm_bt_dai";
		};

		mt_soc_tdmrx_pcm@11220000 {
			compatible = "mediatek,mt_soc_tdm_capture";
		};

		mt_soc_fm_mrgtx_pcm@11220000 {
			compatible = "mediatek,mt_soc_pcm_fmtx";
		};

		mt_soc_ul2_pcm@11220000 {
			compatible = "mediatek,mt_soc_pcm_capture2";
		};

		mt_soc_i2s0_awb_pcm@11220000 {
			compatible = "mediatek,mt_soc_pcm_i2s0_awb";
		};

		mt_soc_voice_md2@11220000 {
			compatible = "mediatek,mt_soc_pcm_voice_md2";
		};

		mt_soc_routing_pcm@11220000 {
			compatible = "mediatek,mt_soc_pcm_routing";
			i2s1clk-gpio = <0x7 0x6>;
			i2s1dat-gpio = <0x5 0x6>;
			i2s1mclk-gpio = <0x9 0x6>;
			i2s1ws-gpio = <0x6 0x6>;
		};

		mt_soc_voice_md2_bt@11220000 {
			compatible = "mediatek,mt_soc_pcm_voice_md2_bt";
		};

		mt_soc_hp_impedance_pcm@11220000 {
			compatible = "mediatek,Mt_soc_pcm_hp_impedance";
		};

		mt_soc_codec_name@11220000 {
			compatible = "mediatek,mt_soc_codec_63xx";
		};

		mt_soc_dummy_pcm@11220000 {
			compatible = "mediatek,mt_soc_pcm_dummy";
		};

		mt_soc_codec_dummy_name@11220000 {
			compatible = "mediatek,mt_soc_codec_dummy";
		};

		mt_soc_routing_dai_name@11220000 {
			compatible = "mediatek,mt_soc_dai_routing";
		};

		mt_soc_dai_name@11220000 {
			compatible = "mediatek,mt_soc_dai_stub";
		};

		mt_soc_offload_gdma@11220000 {
			compatible = "mediatek,mt_soc_pcm_offload_gdma";
		};

		mt_soc_dl2_pcm@11220000 {
			compatible = "mediatek,mt_soc_pcm_dl2";
		};

		pwrap {
			compatible = "mediatek,PWRAP";
			reg = <0x10001000 0x1000>;
			interrupts = <0x0 0xa3 0x4>;
		};

		touch@ {
			compatible = "mediatek,mt6735-touch", "mediatek,mt6735m-touch", "mediatek,mt6753-touch";
			vtouch-supply = <0x71>;
			interrupt-parent = <0xb>;
			interrupts = <0xa 0x2>;
			debounce = <0xa 0x0>;
			status = "okay";
			tpd-resolution = <0x4b0 0x780>;
			use-tpd-button = <0x0>;
			tpd-key-num = <0x3>;
			tpd-key-local = <0x8b 0xac 0x9e 0x0>;
			tpd-key-dim-local = <0x5a 0x373 0x64 0x28 0xe6 0x373 0x64 0x28 0x172 0x373 0x64 0x28 0x0 0x0 0x0 0x0>;
			tpd-max-touch-num = <0x5>;
			tpd-filter-enable = <0x1>;
			tpd-filter-pixel-density = <0xba>;
			tpd-filter-custom-prameters = <0x0 0x0 0x0 0x0 0x0 0x0 0x0 0x0 0x0 0x0 0x0 0x0>;
			tpd-filter-custom-speed = <0x0 0x0 0x0>;
			pinctrl-names = "default", "state_eint_as_int", "state_eint_output0", "state_eint_output1", "state_rst_output0", "state_rst_output1";
			pinctrl-0 = <0x72>;
			pinctrl-1 = <0x73>;
			pinctrl-2 = <0x74>;
			pinctrl-3 = <0x75>;
			pinctrl-4 = <0x76>;
			pinctrl-5 = <0x77>;
		};

		accdet@ {
			compatible = "mediatek,mt6735-accdet", "mediatek,mt6735m-accdet", "mediatek,mt6753-accdet";
			interrupt-parent = <0xb>;
			interrupts = <0x56 0x8>;
			debounce = <0x56 0x3e800>;
			status = "okay";
			eint-debounce = <0x100>;
			accdet-gpio = <0x9 0x56 0x0>;
			accdet-mic-vol = <0x7>;
			headset-mode-setting = <0x500 0x200 0x1 0x1f0 0x800 0x800 0x20>;
			accdet-plugout-debounce = <0x14>;
			accdet-mic-mode = <0x1>;
			headset-three-key-threshold = <0x0 0x50 0xdc 0x1f4>;
			headset-four-key-threshold = <0x0 0x3a 0x79 0xc0 0x1c2>;
			pinctrl-names = "default", "state_eint_as_int";
			pinctrl-0 = <0x78>;
			pinctrl-1 = <0x79>;
		};

		G3D_CONFIG@0x13000000 {
			compatible = "mediatek,G3D_CONFIG";
			reg = <0x13000000 0x1000>;
		};

		MALI@0x13040000 {
			compatible = "arm,malit720", "arm,mali-t72x", "arm,malit7xx", "arm,mali-midgard";
			reg = <0x13040000 0x4000>;
			interrupts = <0x0 0xd6 0x8 0x0 0xd5 0x8 0x0 0xd4 0x8>;
			interrupt-names = "JOB", "MMU", "GPU";
			clock-frequency = <0x1ad27480>;
			clocks = <0x7a 0x1 0x29 0x1 0x2d 0x5 0x2d 0x4>;
			clock-names = "mfg-main", "mfg-smi-common", "mtcmos-mfg", "mtcmos-display";
		};

		pwm@11006000 {
			compatible = "mediatek,pwm";
			reg = <0x11006000 0x1000>;
			interrupts = <0x0 0x4d 0x8>;
		};

		MTKFB@5e200000 {
			compatible = "mediatek,MTKFB";
			reg = <0x7f000000 0x1000000>;
		};
	};

	rf_clock_buffer {
		compatible = "mediatek,rf_clock_buffer";
		mediatek,clkbuf-quantity = <0x4>;
		mediatek,clkbuf-config = <0x2 0x1 0x1 0x1>;
		status = "okay";
	};

	hwmsensor@0 {
		compatible = "mediatek,hwmsensor";
	};

	gsensor@0 {
		compatible = "mediatek,gsensor";
	};

	als_ps@0 {
		compatible = "mediatek,als_ps";
	};

	m_acc_pl@0 {
		compatible = "mediatek,m_acc_pl";
	};

	m_alsps_pl@0 {
		compatible = "mediatek,m_alsps_pl";
	};

	m_batch_pl@0 {
		compatible = "mediatek,m_batch_pl";
	};

	batchsensor@0 {
		compatible = "mediatek,batchsensor";
	};

	gyroscope@0 {
		compatible = "mediatek,gyroscope";
	};

	m_gyro_pl@0 {
		compatible = "mediatek,m_gyro_pl";
	};

	barometer@0 {
		compatible = "mediatek,barometer";
	};

	m_baro_pl@0 {
		compatible = "mediatek,m_baro_pl";
	};

	msensor@0 {
		compatible = "mediatek,msensor";
	};

	m_mag_pl@0 {
		compatible = "mediatek,m_mag_pl";
	};

	orientation@0 {
		compatible = "mediatek,orientation";
	};

	mt8193ckgen@0 {
		compatible = "mediatek,mt8193-ckgen";
	};

	multibridge@0 {
		compatible = "mediatek,multibridge";
	};

	trusty {
		compatible = "android,trusty-smc-v1";
		ranges;
		#address-cells = <0x2>;
		#size-cells = <0x2>;

		irq {
			compatible = "android,trusty-irq-v1";
			ppi-interrupt-parent = <0x1>;
		};

		log {
			compatible = "android,trusty-log-v1";
		};

		virtio {
			compatible = "android,trusty-virtio-v1";
		};

		mtee {
			compatible = "mediatek,trusty-mtee-v1";
		};
	};

	lcm_params {
		compatible = "mediatek,lcm_params-r63417_fhd_dsi_cmd_truly_nt50358_drv";
		lcm_params-types = <0x2 0x0 0x0 0x0>;
		lcm_params-resolution = <0x438 0x780>;
		lcm_params-io_select_mode;
		lcm_params-dbi-port;
		lcm_params-dbi-clock_freq;
		lcm_params-dbi-data_width;
		lcm_params-dbi-data_format;
		lcm_params-dbi-cpu_write_bits;
		lcm_params-dbi-io_driving_current;
		lcm_params-dbi-msb_io_driving_current;
		lcm_params-dbi-ctrl_io_driving_current;
		lcm_params-dbi-te_mode;
		lcm_params-dbi-te_edge_polarity;
		lcm_params-dbi-te_hs_delay_cnt;
		lcm_params-dbi-te_vs_width_cnt;
		lcm_params-dbi-te_vs_width_cnt_div;
		lcm_params-dbi-serial-params0;
		lcm_params-dbi-serial-params1;
		lcm_params-dbi-serial-params2;
		lcm_params-dbi-parallel-params0;
		lcm_params-dbi-parallel-params1;
		lcm_params-dpi-mipi_pll_clk_ref;
		lcm_params-dpi-mipi_pll_clk_div1;
		lcm_params-dpi-mipi_pll_clk_div2;
		lcm_params-dpi-mipi_pll_clk_fbk_div;
		lcm_params-dpi-dpi_clk_div;
		lcm_params-dpi-dpi_clk_duty;
		lcm_params-dpi-PLL_CLOCK;
		lcm_params-dpi-dpi_clock;
		lcm_params-dpi-ssc_disable;
		lcm_params-dpi-ssc_range;
		lcm_params-dpi-width;
		lcm_params-dpi-height;
		lcm_params-dpi-bg_width;
		lcm_params-dpi-bg_height;
		lcm_params-dpi-clk_pol;
		lcm_params-dpi-de_pol;
		lcm_params-dpi-vsync_pol;
		lcm_params-dpi-hsync_pol;
		lcm_params-dpi-hsync_pulse_width;
		lcm_params-dpi-hsync_back_porch;
		lcm_params-dpi-hsync_front_porch;
		lcm_params-dpi-vsync_pulse_width;
		lcm_params-dpi-vsync_back_porch;
		lcm_params-dpi-vsync_front_porch;
		lcm_params-dpi-format;
		lcm_params-dpi-rgb_order;
		lcm_params-dpi-is_serial_output;
		lcm_params-dpi-i2x_en;
		lcm_params-dpi-i2x_edge;
		lcm_params-dpi-embsync;
		lcm_params-dpi-lvds_tx_en;
		lcm_params-dpi-bit_swap;
		lcm_params-dpi-intermediat_buffer_num;
		lcm_params-dpi-io_driving_current;
		lcm_params-dpi-lsb_io_driving_current;
		lcm_params-dsi-mode = <0x0>;
		lcm_params-dsi-switch_mode = <0x2>;
		lcm_params-dsi-DSI_WMEM_CONTI;
		lcm_params-dsi-DSI_RMEM_CONTI;
		lcm_params-dsi-VC_NUM;
		lcm_params-dsi-lane_num = <0x4>;
		lcm_params-dsi-data_format = <0x2 0x0 0x0 0x2>;
		lcm_params-dsi-intermediat_buffer_num;
		lcm_params-dsi-ps = <0x2>;
		lcm_params-dsi-word_count;
		lcm_params-dsi-packet_size = <0x100>;
		lcm_params-dsi-vertical_sync_active = <0x2>;
		lcm_params-dsi-vertical_backporch = <0x8>;
		lcm_params-dsi-vertical_frontporch = <0xa>;
		lcm_params-dsi-vertical_frontporch_for_low_power;
		lcm_params-dsi-vertical_active_line = <0x780>;
		lcm_params-dsi-horizontal_sync_active = <0xa>;
		lcm_params-dsi-horizontal_backporch = <0x3c>;
		lcm_params-dsi-horizontal_frontporch = <0x64>;
		lcm_params-dsi-horizontal_blanking_pixel;
		lcm_params-dsi-horizontal_active_pixel = <0x438>;
		lcm_params-dsi-horizontal_bllp;
		lcm_params-dsi-line_byte;
		lcm_params-dsi-horizontal_sync_active_byte;
		lcm_params-dsi-horizontal_backportch_byte;
		lcm_params-dsi-horizontal_frontporch_byte;
		lcm_params-dsi-rgb_byte;
		lcm_params-dsi-horizontal_sync_active_word_count;
		lcm_params-dsi-horizontal_backporch_word_count;
		lcm_params-dsi-horizontal_frontporch_word_count;
		lcm_params-dsi-HS_TRAIL;
		lcm_params-dsi-ZERO;
		lcm_params-dsi-HS_PRPR;
		lcm_params-dsi-LPX;
		lcm_params-dsi-TA_SACK;
		lcm_params-dsi-TA_GET;
		lcm_params-dsi-TA_SURE;
		lcm_params-dsi-TA_GO;
		lcm_params-dsi-CLK_TRAIL;
		lcm_params-dsi-CLK_ZERO;
		lcm_params-dsi-LPX_WAIT;
		lcm_params-dsi-CONT_DET;
		lcm_params-dsi-CLK_HS_PRPR;
		lcm_params-dsi-CLK_HS_POST;
		lcm_params-dsi-DA_HS_EXIT;
		lcm_params-dsi-CLK_HS_EXIT;
		lcm_params-dsi-pll_select;
		lcm_params-dsi-pll_div1;
		lcm_params-dsi-pll_div2;
		lcm_params-dsi-fbk_div;
		lcm_params-dsi-fbk_sel;
		lcm_params-dsi-rg_bir;
		lcm_params-dsi-rg_bic;
		lcm_params-dsi-rg_bp;
		lcm_params-dsi-pll_clock = <0x1c2>;
		lcm_params-dsi-dsi_clock;
		lcm_params-dsi-ssc_disable;
		lcm_params-dsi-ssc_range;
		lcm_params-dsi-compatibility_for_nvk;
		lcm_params-dsi-cont_clock;
		lcm_params-dsi-ufoe_enable;
		lcm_params-dsi-ufoe_params;
		lcm_params-dsi-edp_panel;
		lcm_params-dsi-customization_esd_check_enable = <0x0>;
		lcm_params-dsi-esd_check_enable = <0x1>;
		lcm_params-dsi-lcm_int_te_monitor;
		lcm_params-dsi-lcm_int_te_period;
		lcm_params-dsi-lcm_ext_te_monitor;
		lcm_params-dsi-lcm_ext_te_enable;
		lcm_params-dsi-noncont_clock;
		lcm_params-dsi-noncont_clock_period;
		lcm_params-dsi-clk_lp_per_line_enable = <0x0>;
		lcm_params-dsi-lcm_esd_check_table0 = <0xa 0x1 0x1c 0x0>;
		lcm_params-dsi-lcm_esd_check_table1;
		lcm_params-dsi-lcm_esd_check_table2;
		lcm_params-dsi-switch_mode_enable = <0x0>;
		lcm_params-dsi-dual_dsi_type;
		lcm_params-dsi-lane_swap_en;
		lcm_params-dsi-lane_swap0;
		lcm_params-dsi-lane_swap1;
		lcm_params-dsi-vertical_vfp_lp;
		lcm_params-physical_width;
		lcm_params-physical_height;
		lcm_params-physical_width_um;
		lcm_params-physical_height_um;
		lcm_params-od_table_size;
		lcm_params-od_table;
	};

	lcm_ops {
		compatible = "mediatek,lcm_ops-r63417_fhd_dsi_cmd_truly_nt50358_drv";
		init = <0x1 0x1 0x1 0x0 0x1 0x2 0x1 0x1 0x1 0x3 0x1 0x1 0x3 0x2 0x1 0xa 0x2 0x1 0x2 0x0 0xa 0x2 0x1 0x2 0x1 0xa 0x3 0x1 0x1 0x1 0x3 0x2 0x1 0x1 0x3 0x1 0x1 0x0 0x3 0x2 0x1 0xa 0x3 0x1 0x1 0x1 0x3 0x2 0x1 0xa 0x4 0x5 0x3 0xb0 0x1 0x0 0x4 0x5 0x3 0xd6 0x1 0x1 0x4 0x5 0x3 0x51 0x1 0xff 0x4 0x5 0x3 0x53 0x1 0xc 0x4 0x5 0x2a 0xc6 0x28 0x77 0x1 0x71 0x7 0x65 0x0 0x0 0x0 0x0 0x0 0x0 0x0 0x0 0x0 0x0 0x0 0x0 0x9 0x19 0x9 0x77 0x1 0x71 0x7 0x65 0x0 0x0 0x0 0x0 0x0 0x0 0x0 0x0 0x0 0x0 0x0 0x0 0x9 0x19 0x9 0x4 0x5 0x20 0xc7 0x1e 0x1 0xc 0x14 0x1e 0x2d 0x3c 0x48 0x58 0x3d 0x44 0x4f 0x5c 0x65 0x6d 0x75 0x1 0xc 0x14 0x1d 0x2c 0x39 0x44 0x54 0x39 0x41 0x4d 0x5a 0x63 0x6b 0x74 0x4 0x5 0x15 0xc8 0x13 0x1 0x0 0xff 0xff 0x0 0xfc 0x0 0x0 0xff 0xff 0x0 0xfc 0x0 0x0 0xff 0xff 0x0 0xfc 0x0 0x4 0x5 0x3 0x35 0x1 0x0 0x4 0x5 0x4 0xb6 0x2 0x3a 0xd3 0x4 0x5 0x2 0x29 0x0 0x4 0x5 0x2 0x11 0x0 0x3 0x2 0x1 0x78>;
		compare_id = <0x3 0x1 0x1 0x1 0x3 0x2 0x1 0x1 0x3 0x1 0x1 0x0 0x3 0x2 0x1 0xa 0x3 0x1 0x1 0x1 0x3 0x2 0x1 0xa 0x4 0x4 0x5 0x1 0x0 0x37 0x2 0x0 0x4 0x7 0x3 0xf4 0x1 0x95>;
		suspend = <0x4 0x5 0x2 0x28 0x0 0x3 0x2 0x1 0x14 0x4 0x5 0x2 0x10 0x0 0x4 0x5 0x3 0xb0 0x1 0x0 0x4 0x5 0x3 0xb1 0x1 0x1 0x3 0x2 0x1 0x50 0x3 0x2 0x1 0xa 0x1 0x1 0x1 0x0 0x1 0x2 0x1 0x1 0x1 0x3 0x1 0x0>;
		backlight = <0x4 0x5 0x3 0x51 0x1 0xff>;
	};

	led@0 {
		compatible = "mediatek,red";
		led_mode = <0x0>;
		data = <0x1>;
		pwm_config = <0x0 0x0 0x0 0x0 0x0>;
	};

	led@1 {
		compatible = "mediatek,green";
		led_mode = <0x0>;
		data = <0x1>;
		pwm_config = <0x0 0x0 0x0 0x0 0x0>;
	};

	led@2 {
		compatible = "mediatek,blue";
		led_mode = <0x0>;
		data = <0x1>;
		pwm_config = <0x0 0x0 0x0 0x0 0x0>;
	};

	led@3 {
		compatible = "mediatek,jogball-backlight";
		led_mode = <0x0>;
		data = <0x1>;
		pwm_config = <0x0 0x0 0x0 0x0 0x0>;
	};

	led@4 {
		compatible = "mediatek,keyboard-backlight";
		led_mode = <0x0>;
		data = <0x1>;
		pwm_config = <0x0 0x0 0x0 0x0 0x0>;
	};

	led@5 {
		compatible = "mediatek,button-backlight";
		led_mode = <0x0>;
		data = <0x1>;
		pwm_config = <0x0 0x0 0x0 0x0 0x0>;
	};

	led@6 {
		compatible = "mediatek,lcd-backlight";
		led_mode = <0x5>;
		data = <0x1>;
		pwm_config = <0x0 0x0 0x0 0x0 0x0>;
	};

	vibrator@0 {
		compatible = "mediatek,vibrator";
		vib_timer = <0x19>;
		vib_limit = <0x9>;
		vib_vol = <0x5>;
	};

	cust_accel@0 {
		compatible = "mediatek,kxtj2_1009_new";
		i2c_num = <0x2>;
		i2c_addr = <0xe 0x0 0x0 0x0>;
		direction = <0x0>;
		power_id = <0xffff>;
		power_vol = <0x0>;
		firlen = <0x0>;
		is_batch_supported = <0x0>;
	};
};
